AUTOSAR XML (schema 00054)
package /AUTOSAR/Platform/BaseTypes
  7 x base type, all with category=FIXED_LENGTH:
    boolean_bt: base-type-size=8, base-type-encoding=BOOLEAN
    uint8_bt: base-type-size=8, base-type-encoding=NONE
    uint16_bt: base-type-size=16, base-type-encoding=NONE
    uint32_bt: base-type-size=32, base-type-encoding=NONE
    sint8_bt: base-type-size=8, base-type-encoding=2C
    sint16_bt: base-type-size=16, base-type-encoding=2C
    sint32_bt: base-type-size=32, base-type-encoding=2C
package /AUTOSAR/Platform/ImplementationDataTypes
  7 x impl type, all with category=VALUE:
    boolean_T: base-type=boolean_bt
    uint8_T: base-type=uint8_bt
    uint16_T: base-type=uint16_bt
    uint32_T: base-type=uint32_bt
    sint8_T: base-type=sint8_bt
    sint16_T: base-type=sint16_bt
    sint32_T: base-type=sint32_bt
package /Taktflow/System
  system TaktflowSystem: category=SYSTEM_EXTRACT
package /Taktflow/Communication
  can cluster CAN_500k: baudrate=500000, protocol-name=CAN
    can physical channel CAN_Physical: comm-connectors=[CVC_Conn, FZC_Conn, RZC_Conn, SC_Conn, BCM_Conn, ICU_Conn, TCU_Conn, Tester_Conn]
      frame EStop_Broadcast_Frame: id 0x1, frame-length=4, can-addressing-mode=STANDARD, can-frame-rx-behavior=CAN-20, can-frame-tx-behavior=CAN-20
        pdu EStop_Broadcast: length=4
          signal EStop_Broadcast_E2E_DataID: start 0, 4 bit, little-endian, data-type-policy=OVERRIDE, transfer-property=PENDING
          signal EStop_Broadcast_E2E_AliveCounter: start 4, 4 bit, little-endian, data-type-policy=OVERRIDE, transfer-property=PENDING
          signal EStop_Broadcast_E2E_CRC8: start 8, 8 bit, little-endian, data-type-policy=OVERRIDE, transfer-property=PENDING
          signal EStop_Broadcast_EStop_Active: start 16, 8 bit, little-endian, data-type-policy=OVERRIDE, transfer-property=PENDING
          signal EStop_Broadcast_EStop_Source: start 24, 8 bit, little-endian, data-type-policy=OVERRIDE, transfer-property=PENDING
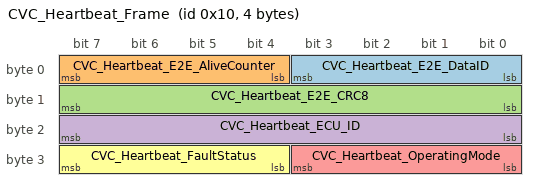
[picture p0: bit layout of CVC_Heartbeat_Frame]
      frame CVC_Heartbeat_Frame: id 0x10, frame-length=4, can-addressing-mode=STANDARD, can-frame-rx-behavior=CAN-20, can-frame-tx-behavior=CAN-20
        pdu CVC_Heartbeat: length=4
          signal CVC_Heartbeat_E2E_DataID: start 0, 4 bit, little-endian, data-type-policy=OVERRIDE, transfer-property=PENDING
          signal CVC_Heartbeat_E2E_AliveCounter: start 4, 4 bit, little-endian, data-type-policy=OVERRIDE, transfer-property=PENDING
          signal CVC_Heartbeat_E2E_CRC8: start 8, 8 bit, little-endian, data-type-policy=OVERRIDE, transfer-property=PENDING
          signal CVC_Heartbeat_ECU_ID: start 16, 8 bit, little-endian, data-type-policy=OVERRIDE, transfer-property=PENDING
          signal CVC_Heartbeat_OperatingMode: start 24, 4 bit, little-endian, data-type-policy=OVERRIDE, transfer-property=PENDING
          signal CVC_Heartbeat_FaultStatus: start 28, 4 bit, little-endian, data-type-policy=OVERRIDE, transfer-property=PENDING
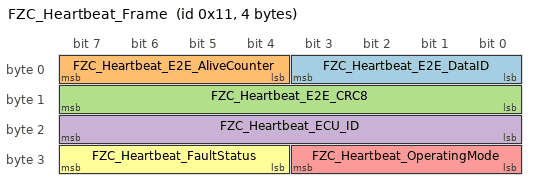
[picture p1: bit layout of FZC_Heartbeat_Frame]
      frame FZC_Heartbeat_Frame: id 0x11, frame-length=4, can-addressing-mode=STANDARD, can-frame-rx-behavior=CAN-20, can-frame-tx-behavior=CAN-20
        pdu FZC_Heartbeat: length=4
          signal FZC_Heartbeat_E2E_DataID: start 0, 4 bit, little-endian, data-type-policy=OVERRIDE, transfer-property=PENDING
          signal FZC_Heartbeat_E2E_AliveCounter: start 4, 4 bit, little-endian, data-type-policy=OVERRIDE, transfer-property=PENDING
          signal FZC_Heartbeat_E2E_CRC8: start 8, 8 bit, little-endian, data-type-policy=OVERRIDE, transfer-property=PENDING
          signal FZC_Heartbeat_ECU_ID: start 16, 8 bit, little-endian, data-type-policy=OVERRIDE, transfer-property=PENDING
          signal FZC_Heartbeat_OperatingMode: start 24, 4 bit, little-endian, data-type-policy=OVERRIDE, transfer-property=PENDING
          signal FZC_Heartbeat_FaultStatus: start 28, 4 bit, little-endian, data-type-policy=OVERRIDE, transfer-property=PENDING
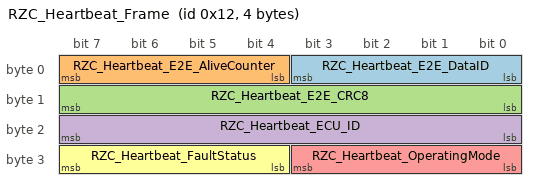
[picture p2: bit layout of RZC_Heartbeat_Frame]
      frame RZC_Heartbeat_Frame: id 0x12, frame-length=4, can-addressing-mode=STANDARD, can-frame-rx-behavior=CAN-20, can-frame-tx-behavior=CAN-20
        pdu RZC_Heartbeat: length=4
          signal RZC_Heartbeat_E2E_DataID: start 0, 4 bit, little-endian, data-type-policy=OVERRIDE, transfer-property=PENDING
          signal RZC_Heartbeat_E2E_AliveCounter: start 4, 4 bit, little-endian, data-type-policy=OVERRIDE, transfer-property=PENDING
          signal RZC_Heartbeat_E2E_CRC8: start 8, 8 bit, little-endian, data-type-policy=OVERRIDE, transfer-property=PENDING
          signal RZC_Heartbeat_ECU_ID: start 16, 8 bit, little-endian, data-type-policy=OVERRIDE, transfer-property=PENDING
          signal RZC_Heartbeat_OperatingMode: start 24, 4 bit, little-endian, data-type-policy=OVERRIDE, transfer-property=PENDING
          signal RZC_Heartbeat_FaultStatus: start 28, 4 bit, little-endian, data-type-policy=OVERRIDE, transfer-property=PENDING
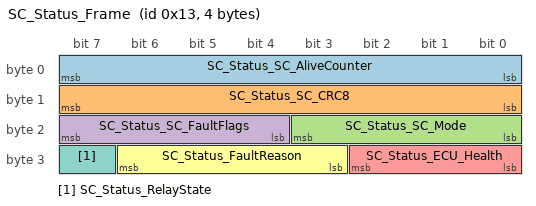
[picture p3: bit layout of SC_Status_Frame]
      frame SC_Status_Frame: id 0x13, frame-length=4, can-addressing-mode=STANDARD, can-frame-rx-behavior=CAN-20, can-frame-tx-behavior=CAN-20
        pdu SC_Status: length=4
          signal SC_Status_SC_AliveCounter: start 0, 8 bit, little-endian, data-type-policy=OVERRIDE, transfer-property=PENDING
          signal SC_Status_SC_CRC8: start 8, 8 bit, little-endian, data-type-policy=OVERRIDE, transfer-property=PENDING
          signal SC_Status_SC_Mode: start 16, 4 bit, little-endian, data-type-policy=OVERRIDE, transfer-property=PENDING
          signal SC_Status_SC_FaultFlags: start 20, 4 bit, little-endian, data-type-policy=OVERRIDE, transfer-property=PENDING
          signal SC_Status_ECU_Health: start 24, 3 bit, little-endian, data-type-policy=OVERRIDE, transfer-property=PENDING
          signal SC_Status_FaultReason: start 27, 4 bit, little-endian, data-type-policy=OVERRIDE, transfer-property=PENDING
          signal SC_Status_RelayState: start 31, 1 bit, little-endian, data-type-policy=OVERRIDE, transfer-property=PENDING
      frame ICU_Heartbeat_Frame: id 0x14, frame-length=4, can-addressing-mode=STANDARD, can-frame-rx-behavior=CAN-20, can-frame-tx-behavior=CAN-20
        pdu ICU_Heartbeat: length=4
          signal ICU_Heartbeat_E2E_DataID: start 0, 4 bit, little-endian, data-type-policy=OVERRIDE, transfer-property=PENDING
          signal ICU_Heartbeat_E2E_AliveCounter: start 4, 4 bit, little-endian, data-type-policy=OVERRIDE, transfer-property=PENDING
          signal ICU_Heartbeat_E2E_CRC8: start 8, 8 bit, little-endian, data-type-policy=OVERRIDE, transfer-property=PENDING
          signal ICU_Heartbeat_AliveCounter: start 16, 8 bit, little-endian, data-type-policy=OVERRIDE, transfer-property=PENDING
          signal ICU_Heartbeat_ECU_ID: start 24, 8 bit, little-endian, data-type-policy=OVERRIDE, transfer-property=PENDING
      frame TCU_Heartbeat_Frame: id 0x15, frame-length=4, can-addressing-mode=STANDARD, can-frame-rx-behavior=CAN-20, can-frame-tx-behavior=CAN-20
        pdu TCU_Heartbeat: length=4
          signal TCU_Heartbeat_E2E_DataID: start 0, 4 bit, little-endian, data-type-policy=OVERRIDE, transfer-property=PENDING
          signal TCU_Heartbeat_E2E_AliveCounter: start 4, 4 bit, little-endian, data-type-policy=OVERRIDE, transfer-property=PENDING
          signal TCU_Heartbeat_E2E_CRC8: start 8, 8 bit, little-endian, data-type-policy=OVERRIDE, transfer-property=PENDING
          signal TCU_Heartbeat_AliveCounter: start 16, 8 bit, little-endian, data-type-policy=OVERRIDE, transfer-property=PENDING
          signal TCU_Heartbeat_ECU_ID: start 24, 8 bit, little-endian, data-type-policy=OVERRIDE, transfer-property=PENDING
      frame BCM_Heartbeat_Frame: id 0x16, frame-length=4, can-addressing-mode=STANDARD, can-frame-rx-behavior=CAN-20, can-frame-tx-behavior=CAN-20
        pdu BCM_Heartbeat: length=4
          signal BCM_Heartbeat_E2E_DataID: start 0, 4 bit, little-endian, data-type-policy=OVERRIDE, transfer-property=PENDING
          signal BCM_Heartbeat_E2E_AliveCounter: start 4, 4 bit, little-endian, data-type-policy=OVERRIDE, transfer-property=PENDING
          signal BCM_Heartbeat_E2E_CRC8: start 8, 8 bit, little-endian, data-type-policy=OVERRIDE, transfer-property=PENDING
          signal BCM_Heartbeat_AliveCounter: start 16, 8 bit, little-endian, data-type-policy=OVERRIDE, transfer-property=PENDING
          signal BCM_Heartbeat_ECU_ID: start 24, 8 bit, little-endian, data-type-policy=OVERRIDE, transfer-property=PENDING
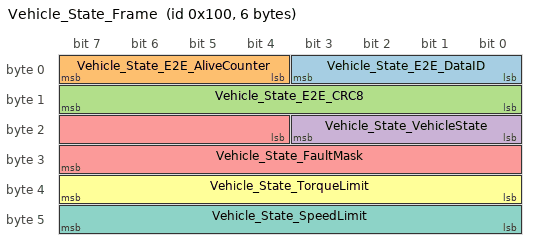
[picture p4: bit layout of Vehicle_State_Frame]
      frame Vehicle_State_Frame: id 0x100, frame-length=6, can-addressing-mode=STANDARD, can-frame-rx-behavior=CAN-20, can-frame-tx-behavior=CAN-20
        pdu Vehicle_State: length=6
          signal Vehicle_State_E2E_DataID: start 0, 4 bit, little-endian, data-type-policy=OVERRIDE, transfer-property=PENDING
          signal Vehicle_State_E2E_AliveCounter: start 4, 4 bit, little-endian, data-type-policy=OVERRIDE, transfer-property=PENDING
          signal Vehicle_State_E2E_CRC8: start 8, 8 bit, little-endian, data-type-policy=OVERRIDE, transfer-property=PENDING
          signal Vehicle_State_VehicleState: start 16, 4 bit, little-endian, data-type-policy=OVERRIDE, transfer-property=PENDING
          signal Vehicle_State_FaultMask: start 20, 12 bit, little-endian, data-type-policy=OVERRIDE, transfer-property=PENDING
          signal Vehicle_State_TorqueLimit: start 32, 8 bit, little-endian, data-type-policy=OVERRIDE, transfer-property=PENDING
          signal Vehicle_State_SpeedLimit: start 40, 8 bit, little-endian, data-type-policy=OVERRIDE, transfer-property=PENDING
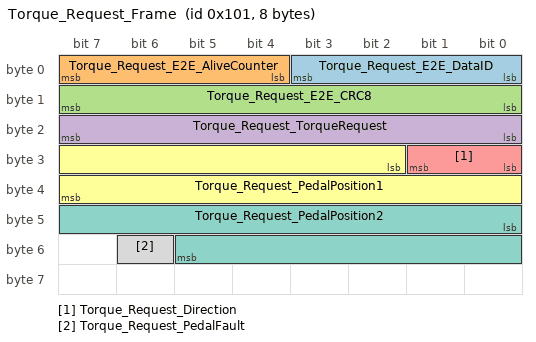
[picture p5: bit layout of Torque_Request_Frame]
      frame Torque_Request_Frame: id 0x101, frame-length=8, can-addressing-mode=STANDARD, can-frame-rx-behavior=CAN-20, can-frame-tx-behavior=CAN-20
        pdu Torque_Request: length=8
          signal Torque_Request_E2E_DataID: start 0, 4 bit, little-endian, data-type-policy=OVERRIDE, transfer-property=PENDING
          signal Torque_Request_E2E_AliveCounter: start 4, 4 bit, little-endian, data-type-policy=OVERRIDE, transfer-property=PENDING
          signal Torque_Request_E2E_CRC8: start 8, 8 bit, little-endian, data-type-policy=OVERRIDE, transfer-property=PENDING
          signal Torque_Request_TorqueRequest: start 16, 8 bit, little-endian, data-type-policy=OVERRIDE, transfer-property=PENDING
          signal Torque_Request_Direction: start 24, 2 bit, little-endian, data-type-policy=OVERRIDE, transfer-property=PENDING
          signal Torque_Request_PedalPosition1: start 26, 14 bit, little-endian, data-type-policy=OVERRIDE, transfer-property=PENDING
          signal Torque_Request_PedalPosition2: start 40, 14 bit, little-endian, data-type-policy=OVERRIDE, transfer-property=PENDING
          signal Torque_Request_PedalFault: start 54, 1 bit, little-endian, data-type-policy=OVERRIDE, transfer-property=PENDING
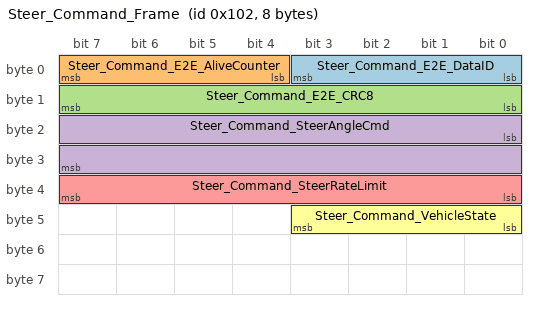
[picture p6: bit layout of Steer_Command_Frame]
      frame Steer_Command_Frame: id 0x102, frame-length=8, can-addressing-mode=STANDARD, can-frame-rx-behavior=CAN-20, can-frame-tx-behavior=CAN-20
        pdu Steer_Command: length=8
          signal Steer_Command_E2E_DataID: start 0, 4 bit, little-endian, data-type-policy=OVERRIDE, transfer-property=PENDING
          signal Steer_Command_E2E_AliveCounter: start 4, 4 bit, little-endian, data-type-policy=OVERRIDE, transfer-property=PENDING
          signal Steer_Command_E2E_CRC8: start 8, 8 bit, little-endian, data-type-policy=OVERRIDE, transfer-property=PENDING
          signal Steer_Command_SteerAngleCmd: start 16, 16 bit, little-endian, data-type-policy=OVERRIDE, transfer-property=PENDING
          signal Steer_Command_SteerRateLimit: start 32, 8 bit, little-endian, data-type-policy=OVERRIDE, transfer-property=PENDING
          signal Steer_Command_VehicleState: start 40, 4 bit, little-endian, data-type-policy=OVERRIDE, transfer-property=PENDING
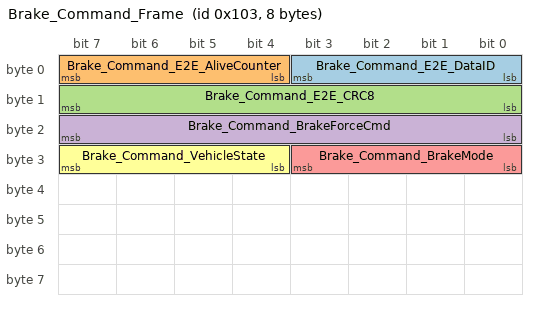
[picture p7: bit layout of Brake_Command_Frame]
      frame Brake_Command_Frame: id 0x103, frame-length=8, can-addressing-mode=STANDARD, can-frame-rx-behavior=CAN-20, can-frame-tx-behavior=CAN-20
        pdu Brake_Command: length=8
          signal Brake_Command_E2E_DataID: start 0, 4 bit, little-endian, data-type-policy=OVERRIDE, transfer-property=PENDING
          signal Brake_Command_E2E_AliveCounter: start 4, 4 bit, little-endian, data-type-policy=OVERRIDE, transfer-property=PENDING
          signal Brake_Command_E2E_CRC8: start 8, 8 bit, little-endian, data-type-policy=OVERRIDE, transfer-property=PENDING
          signal Brake_Command_BrakeForceCmd: start 16, 8 bit, little-endian, data-type-policy=OVERRIDE, transfer-property=PENDING
          signal Brake_Command_BrakeMode: start 24, 4 bit, little-endian, data-type-policy=OVERRIDE, transfer-property=PENDING
          signal Brake_Command_VehicleState: start 28, 4 bit, little-endian, data-type-policy=OVERRIDE, transfer-property=PENDING
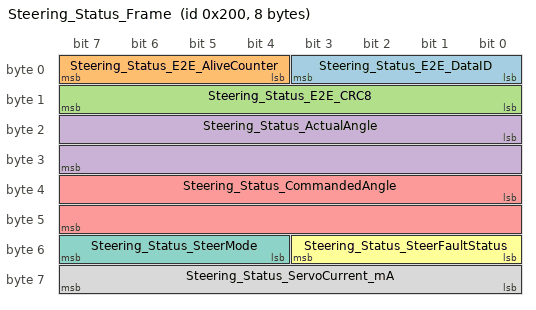
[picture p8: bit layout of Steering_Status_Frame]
      frame Steering_Status_Frame: id 0x200, frame-length=8, can-addressing-mode=STANDARD, can-frame-rx-behavior=CAN-20, can-frame-tx-behavior=CAN-20
        pdu Steering_Status: length=8
          signal Steering_Status_E2E_DataID: start 0, 4 bit, little-endian, data-type-policy=OVERRIDE, transfer-property=PENDING
          signal Steering_Status_E2E_AliveCounter: start 4, 4 bit, little-endian, data-type-policy=OVERRIDE, transfer-property=PENDING
          signal Steering_Status_E2E_CRC8: start 8, 8 bit, little-endian, data-type-policy=OVERRIDE, transfer-property=PENDING
          signal Steering_Status_ActualAngle: start 16, 16 bit, little-endian, data-type-policy=OVERRIDE, transfer-property=PENDING
          signal Steering_Status_CommandedAngle: start 32, 16 bit, little-endian, data-type-policy=OVERRIDE, transfer-property=PENDING
          signal Steering_Status_SteerFaultStatus: start 48, 4 bit, little-endian, data-type-policy=OVERRIDE, transfer-property=PENDING
          signal Steering_Status_SteerMode: start 52, 4 bit, little-endian, data-type-policy=OVERRIDE, transfer-property=PENDING
          signal Steering_Status_ServoCurrent_mA: start 56, 8 bit, little-endian, data-type-policy=OVERRIDE, transfer-property=PENDING
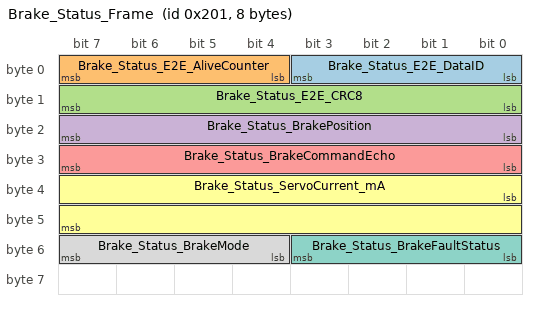
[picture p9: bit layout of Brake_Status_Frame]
      frame Brake_Status_Frame: id 0x201, frame-length=8, can-addressing-mode=STANDARD, can-frame-rx-behavior=CAN-20, can-frame-tx-behavior=CAN-20
        pdu Brake_Status: length=8
          signal Brake_Status_E2E_DataID: start 0, 4 bit, little-endian, data-type-policy=OVERRIDE, transfer-property=PENDING
          signal Brake_Status_E2E_AliveCounter: start 4, 4 bit, little-endian, data-type-policy=OVERRIDE, transfer-property=PENDING
          signal Brake_Status_E2E_CRC8: start 8, 8 bit, little-endian, data-type-policy=OVERRIDE, transfer-property=PENDING
          signal Brake_Status_BrakePosition: start 16, 8 bit, little-endian, data-type-policy=OVERRIDE, transfer-property=PENDING
          signal Brake_Status_BrakeCommandEcho: start 24, 8 bit, little-endian, data-type-policy=OVERRIDE, transfer-property=PENDING
          signal Brake_Status_ServoCurrent_mA: start 32, 16 bit, little-endian, data-type-policy=OVERRIDE, transfer-property=PENDING
          signal Brake_Status_BrakeFaultStatus: start 48, 4 bit, little-endian, data-type-policy=OVERRIDE, transfer-property=PENDING
          signal Brake_Status_BrakeMode: start 52, 4 bit, little-endian, data-type-policy=OVERRIDE, transfer-property=PENDING
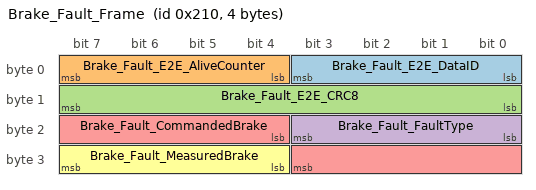
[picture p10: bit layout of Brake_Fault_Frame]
      frame Brake_Fault_Frame: id 0x210, frame-length=4, can-addressing-mode=STANDARD, can-frame-rx-behavior=CAN-20, can-frame-tx-behavior=CAN-20
        pdu Brake_Fault: length=4
          signal Brake_Fault_E2E_DataID: start 0, 4 bit, little-endian, data-type-policy=OVERRIDE, transfer-property=PENDING
          signal Brake_Fault_E2E_AliveCounter: start 4, 4 bit, little-endian, data-type-policy=OVERRIDE, transfer-property=PENDING
          signal Brake_Fault_E2E_CRC8: start 8, 8 bit, little-endian, data-type-policy=OVERRIDE, transfer-property=PENDING
          signal Brake_Fault_FaultType: start 16, 4 bit, little-endian, data-type-policy=OVERRIDE, transfer-property=PENDING
          signal Brake_Fault_CommandedBrake: start 20, 8 bit, little-endian, data-type-policy=OVERRIDE, transfer-property=PENDING
          signal Brake_Fault_MeasuredBrake: start 28, 4 bit, little-endian, data-type-policy=OVERRIDE, transfer-property=PENDING
      frame Motor_Cutoff_Req_Frame: id 0x211, frame-length=4, can-addressing-mode=STANDARD, can-frame-rx-behavior=CAN-20, can-frame-tx-behavior=CAN-20
        pdu Motor_Cutoff_Req: length=4
          signal Motor_Cutoff_Req_E2E_DataID: start 0, 4 bit, little-endian, data-type-policy=OVERRIDE, transfer-property=PENDING
          signal Motor_Cutoff_Req_E2E_AliveCounter: start 4, 4 bit, little-endian, data-type-policy=OVERRIDE, transfer-property=PENDING
          signal Motor_Cutoff_Req_E2E_CRC8: start 8, 8 bit, little-endian, data-type-policy=OVERRIDE, transfer-property=PENDING
          signal Motor_Cutoff_Req_RequestType: start 16, 4 bit, little-endian, data-type-policy=OVERRIDE, transfer-property=PENDING
          signal Motor_Cutoff_Req_Reason: start 20, 4 bit, little-endian, data-type-policy=OVERRIDE, transfer-property=PENDING
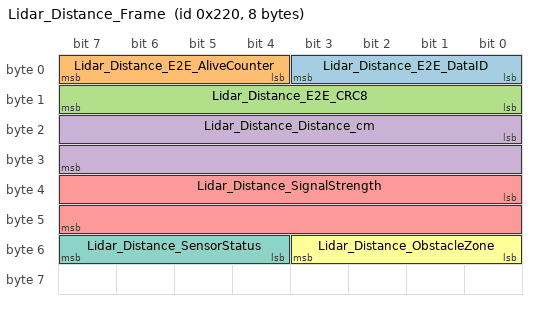
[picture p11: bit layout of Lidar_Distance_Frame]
      frame Lidar_Distance_Frame: id 0x220, frame-length=8, can-addressing-mode=STANDARD, can-frame-rx-behavior=CAN-20, can-frame-tx-behavior=CAN-20
        pdu Lidar_Distance: length=8
          signal Lidar_Distance_E2E_DataID: start 0, 4 bit, little-endian, data-type-policy=OVERRIDE, transfer-property=PENDING
          signal Lidar_Distance_E2E_AliveCounter: start 4, 4 bit, little-endian, data-type-policy=OVERRIDE, transfer-property=PENDING
          signal Lidar_Distance_E2E_CRC8: start 8, 8 bit, little-endian, data-type-policy=OVERRIDE, transfer-property=PENDING
          signal Lidar_Distance_Distance_cm: start 16, 16 bit, little-endian, data-type-policy=OVERRIDE, transfer-property=PENDING
          signal Lidar_Distance_SignalStrength: start 32, 16 bit, little-endian, data-type-policy=OVERRIDE, transfer-property=PENDING
          signal Lidar_Distance_ObstacleZone: start 48, 4 bit, little-endian, data-type-policy=OVERRIDE, transfer-property=PENDING
          signal Lidar_Distance_SensorStatus: start 52, 4 bit, little-endian, data-type-policy=OVERRIDE, transfer-property=PENDING
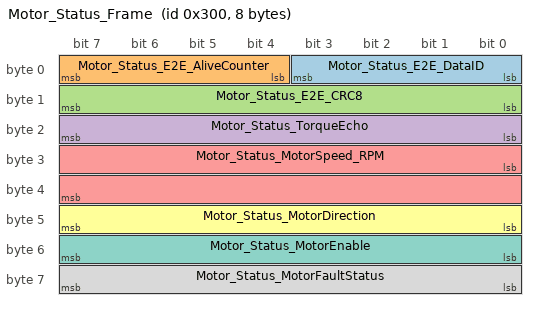
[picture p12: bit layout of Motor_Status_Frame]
      frame Motor_Status_Frame: id 0x300, frame-length=8, can-addressing-mode=STANDARD, can-frame-rx-behavior=CAN-20, can-frame-tx-behavior=CAN-20
        pdu Motor_Status: length=8
          signal Motor_Status_E2E_DataID: start 0, 4 bit, little-endian, data-type-policy=OVERRIDE, transfer-property=PENDING
          signal Motor_Status_E2E_AliveCounter: start 4, 4 bit, little-endian, data-type-policy=OVERRIDE, transfer-property=PENDING
          signal Motor_Status_E2E_CRC8: start 8, 8 bit, little-endian, data-type-policy=OVERRIDE, transfer-property=PENDING
          signal Motor_Status_TorqueEcho: start 16, 8 bit, little-endian, data-type-policy=OVERRIDE, transfer-property=PENDING
          signal Motor_Status_MotorSpeed_RPM: start 24, 16 bit, little-endian, data-type-policy=OVERRIDE, transfer-property=PENDING
          signal Motor_Status_MotorDirection: start 40, 8 bit, little-endian, data-type-policy=OVERRIDE, transfer-property=PENDING
          signal Motor_Status_MotorEnable: start 48, 8 bit, little-endian, data-type-policy=OVERRIDE, transfer-property=PENDING
          signal Motor_Status_MotorFaultStatus: start 56, 8 bit, little-endian, data-type-policy=OVERRIDE, transfer-property=PENDING
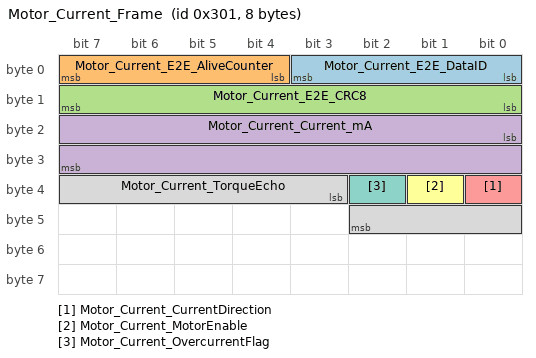
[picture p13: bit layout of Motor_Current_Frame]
      frame Motor_Current_Frame: id 0x301, frame-length=8, can-addressing-mode=STANDARD, can-frame-rx-behavior=CAN-20, can-frame-tx-behavior=CAN-20
        pdu Motor_Current: length=8
          signal Motor_Current_E2E_DataID: start 0, 4 bit, little-endian, data-type-policy=OVERRIDE, transfer-property=PENDING
          signal Motor_Current_E2E_AliveCounter: start 4, 4 bit, little-endian, data-type-policy=OVERRIDE, transfer-property=PENDING
          signal Motor_Current_E2E_CRC8: start 8, 8 bit, little-endian, data-type-policy=OVERRIDE, transfer-property=PENDING
          signal Motor_Current_Current_mA: start 16, 16 bit, little-endian, data-type-policy=OVERRIDE, transfer-property=PENDING
          signal Motor_Current_CurrentDirection: start 32, 1 bit, little-endian, data-type-policy=OVERRIDE, transfer-property=PENDING
          signal Motor_Current_MotorEnable: start 33, 1 bit, little-endian, data-type-policy=OVERRIDE, transfer-property=PENDING
          signal Motor_Current_OvercurrentFlag: start 34, 1 bit, little-endian, data-type-policy=OVERRIDE, transfer-property=PENDING
          signal Motor_Current_TorqueEcho: start 35, 8 bit, little-endian, data-type-policy=OVERRIDE, transfer-property=PENDING
      frame Motor_Temperature_Frame: id 0x302, frame-length=8, can-addressing-mode=STANDARD, can-frame-rx-behavior=CAN-20, can-frame-tx-behavior=CAN-20
        pdu Motor_Temperature: length=8
          signal Motor_Temperature_E2E_DataID: start 0, 4 bit, little-endian, data-type-policy=OVERRIDE, transfer-property=PENDING
          signal Motor_Temperature_E2E_AliveCounter: start 4, 4 bit, little-endian, data-type-policy=OVERRIDE, transfer-property=PENDING
          signal Motor_Temperature_E2E_CRC8: start 8, 8 bit, little-endian, data-type-policy=OVERRIDE, transfer-property=PENDING
          signal Motor_Temperature_WindingTemp1_C: start 16, 16 bit, little-endian, data-type-policy=OVERRIDE, transfer-property=PENDING
          signal Motor_Temperature_WindingTemp2_C: start 32, 16 bit, little-endian, data-type-policy=OVERRIDE, transfer-property=PENDING
          signal Motor_Temperature_DeratingPercent: start 48, 8 bit, little-endian, data-type-policy=OVERRIDE, transfer-property=PENDING
      frame Battery_Status_Frame: id 0x303, frame-length=6, can-addressing-mode=STANDARD, can-frame-rx-behavior=CAN-20, can-frame-tx-behavior=CAN-20
        pdu Battery_Status: length=6
          signal Battery_Status_E2E_DataID: start 0, 4 bit, little-endian, data-type-policy=OVERRIDE, transfer-property=PENDING
          signal Battery_Status_E2E_AliveCounter: start 4, 4 bit, little-endian, data-type-policy=OVERRIDE, transfer-property=PENDING
          signal Battery_Status_E2E_CRC8: start 8, 8 bit, little-endian, data-type-policy=OVERRIDE, transfer-property=PENDING
          signal Battery_Status_BatteryVoltage_mV: start 16, 16 bit, little-endian, data-type-policy=OVERRIDE, transfer-property=PENDING
          signal Battery_Status_BatteryStatus: start 32, 8 bit, little-endian, data-type-policy=OVERRIDE, transfer-property=PENDING
      frame Body_Control_Cmd_Frame: id 0x350, frame-length=4, can-addressing-mode=STANDARD, can-frame-rx-behavior=CAN-20, can-frame-tx-behavior=CAN-20
        pdu Body_Control_Cmd: length=4
          signal Body_Control_Cmd_HeadlightCmd: start 0, 2 bit, little-endian, data-type-policy=OVERRIDE, transfer-property=PENDING
          signal Body_Control_Cmd_TailLightCmd: start 2, 1 bit, little-endian, data-type-policy=OVERRIDE, transfer-property=PENDING
          signal Body_Control_Cmd_HazardCmd: start 3, 1 bit, little-endian, data-type-policy=OVERRIDE, transfer-property=PENDING
          signal Body_Control_Cmd_TurnSignalCmd: start 4, 2 bit, little-endian, data-type-policy=OVERRIDE, transfer-property=PENDING
          signal Body_Control_Cmd_DoorLockCmd: start 6, 1 bit, little-endian, data-type-policy=OVERRIDE, transfer-property=PENDING
      frame Light_Status_Frame: id 0x400, frame-length=4, can-addressing-mode=STANDARD, can-frame-rx-behavior=CAN-20, can-frame-tx-behavior=CAN-20
        pdu Light_Status: length=4
          signal Light_Status_HeadlightOn: start 0, 1 bit, little-endian, data-type-policy=OVERRIDE, transfer-property=PENDING
          signal Light_Status_TailLightOn: start 1, 1 bit, little-endian, data-type-policy=OVERRIDE, transfer-property=PENDING
          signal Light_Status_FogLightOn: start 2, 1 bit, little-endian, data-type-policy=OVERRIDE, transfer-property=PENDING
          signal Light_Status_BrakeLightOn: start 3, 1 bit, little-endian, data-type-policy=OVERRIDE, transfer-property=PENDING
          signal Light_Status_HeadlightLevel: start 4, 2 bit, little-endian, data-type-policy=OVERRIDE, transfer-property=PENDING
      frame Indicator_State_Frame: id 0x401, frame-length=4, can-addressing-mode=STANDARD, can-frame-rx-behavior=CAN-20, can-frame-tx-behavior=CAN-20
        pdu Indicator_State: length=4
          signal Indicator_State_LeftIndicator: start 0, 1 bit, little-endian, data-type-policy=OVERRIDE, transfer-property=PENDING
          signal Indicator_State_RightIndicator: start 1, 1 bit, little-endian, data-type-policy=OVERRIDE, transfer-property=PENDING
          signal Indicator_State_HazardActive: start 2, 1 bit, little-endian, data-type-policy=OVERRIDE, transfer-property=PENDING
          signal Indicator_State_BlinkState: start 3, 1 bit, little-endian, data-type-policy=OVERRIDE, transfer-property=PENDING
      frame Door_Lock_Status_Frame: id 0x402, frame-length=2, can-addressing-mode=STANDARD, can-frame-rx-behavior=CAN-20, can-frame-tx-behavior=CAN-20
        pdu Door_Lock_Status: length=2
          signal Door_Lock_Status_FrontLeftLock: start 0, 1 bit, little-endian, data-type-policy=OVERRIDE, transfer-property=PENDING
          signal Door_Lock_Status_FrontRightLock: start 1, 1 bit, little-endian, data-type-policy=OVERRIDE, transfer-property=PENDING
          signal Door_Lock_Status_RearLeftLock: start 2, 1 bit, little-endian, data-type-policy=OVERRIDE, transfer-property=PENDING
          signal Door_Lock_Status_RearRightLock: start 3, 1 bit, little-endian, data-type-policy=OVERRIDE, transfer-property=PENDING
          signal Door_Lock_Status_CentralLock: start 4, 1 bit, little-endian, data-type-policy=OVERRIDE, transfer-property=PENDING
      frame DTC_Broadcast_Frame: id 0x500, frame-length=8, can-addressing-mode=STANDARD, can-frame-rx-behavior=CAN-20, can-frame-tx-behavior=CAN-20
        pdu DTC_Broadcast: length=8
          signal DTC_Broadcast_DTC_Number: start 7, 24 bit, big-endian, data-type-policy=OVERRIDE, transfer-property=PENDING
          signal DTC_Broadcast_DTC_Status: start 24, 8 bit, little-endian, data-type-policy=OVERRIDE, transfer-property=PENDING
          signal DTC_Broadcast_ECU_Source: start 32, 8 bit, little-endian, data-type-policy=OVERRIDE, transfer-property=PENDING
          signal DTC_Broadcast_OccurrenceCount: start 40, 8 bit, little-endian, data-type-policy=OVERRIDE, transfer-property=PENDING
          signal DTC_Broadcast_FreezeFrame0: start 48, 8 bit, little-endian, data-type-policy=OVERRIDE, transfer-property=PENDING
          signal DTC_Broadcast_FreezeFrame1: start 56, 8 bit, little-endian, data-type-policy=OVERRIDE, transfer-property=PENDING
      frame UDS_Func_Request_Frame: id 0x7DF, frame-length=8, can-addressing-mode=STANDARD, can-frame-rx-behavior=CAN-20, can-frame-tx-behavior=CAN-20
        pdu UDS_Func_Request: length=8
          signal UDS_Func_Request_UDS_Data: start 0, 64 bit, little-endian, data-type-policy=OVERRIDE, transfer-property=PENDING
      frame UDS_Phys_Req_CVC_Frame: id 0x7E0, frame-length=8, can-addressing-mode=STANDARD, can-frame-rx-behavior=CAN-20, can-frame-tx-behavior=CAN-20
        pdu UDS_Phys_Req_CVC: length=8
          signal UDS_Phys_Req_CVC_UDS_Data: start 0, 64 bit, little-endian, data-type-policy=OVERRIDE, transfer-property=PENDING
      frame UDS_Phys_Req_FZC_Frame: id 0x7E1, frame-length=8, can-addressing-mode=STANDARD, can-frame-rx-behavior=CAN-20, can-frame-tx-behavior=CAN-20
        pdu UDS_Phys_Req_FZC: length=8
          signal UDS_Phys_Req_FZC_UDS_Data: start 0, 64 bit, little-endian, data-type-policy=OVERRIDE, transfer-property=PENDING
      frame UDS_Phys_Req_RZC_Frame: id 0x7E2, frame-length=8, can-addressing-mode=STANDARD, can-frame-rx-behavior=CAN-20, can-frame-tx-behavior=CAN-20
        pdu UDS_Phys_Req_RZC: length=8
          signal UDS_Phys_Req_RZC_UDS_Data: start 0, 64 bit, little-endian, data-type-policy=OVERRIDE, transfer-property=PENDING
      frame UDS_Phys_Req_TCU_Frame: id 0x7E3, frame-length=8, can-addressing-mode=STANDARD, can-frame-rx-behavior=CAN-20, can-frame-tx-behavior=CAN-20
        pdu UDS_Phys_Req_TCU: length=8
          signal UDS_Phys_Req_TCU_UDS_Data: start 0, 64 bit, little-endian, data-type-policy=OVERRIDE, transfer-property=PENDING
      frame UDS_Resp_CVC_Frame: id 0x7E8, frame-length=8, can-addressing-mode=STANDARD, can-frame-rx-behavior=CAN-20, can-frame-tx-behavior=CAN-20
        pdu UDS_Resp_CVC: length=8
          signal UDS_Resp_CVC_UDS_Data: start 0, 64 bit, little-endian, data-type-policy=OVERRIDE, transfer-property=PENDING
      frame UDS_Resp_FZC_Frame: id 0x7E9, frame-length=8, can-addressing-mode=STANDARD, can-frame-rx-behavior=CAN-20, can-frame-tx-behavior=CAN-20
        pdu UDS_Resp_FZC: length=8
          signal UDS_Resp_FZC_UDS_Data: start 0, 64 bit, little-endian, data-type-policy=OVERRIDE, transfer-property=PENDING
      frame UDS_Resp_RZC_Frame: id 0x7EA, frame-length=8, can-addressing-mode=STANDARD, can-frame-rx-behavior=CAN-20, can-frame-tx-behavior=CAN-20
        pdu UDS_Resp_RZC: length=8
          signal UDS_Resp_RZC_UDS_Data: start 0, 64 bit, little-endian, data-type-policy=OVERRIDE, transfer-property=PENDING
      frame UDS_Resp_TCU_Frame: id 0x644, frame-length=8, can-addressing-mode=STANDARD, can-frame-rx-behavior=CAN-20, can-frame-tx-behavior=CAN-20
        pdu UDS_Resp_TCU: length=8
          signal UDS_Resp_TCU_UDS_Data: start 0, 64 bit, little-endian, data-type-policy=OVERRIDE, transfer-property=PENDING
package /Taktflow/ECUs
  8 x ecu instance:
    CVC
      can communication controller CVC_CanCtrl
      can communication connector CVC_Conn: comm-controller=CVC_CanCtrl
    FZC
      can communication controller FZC_CanCtrl
      can communication connector FZC_Conn: comm-controller=FZC_CanCtrl
    RZC
      can communication controller RZC_CanCtrl
      can communication connector RZC_Conn: comm-controller=RZC_CanCtrl
    SC
      can communication controller SC_CanCtrl
      can communication connector SC_Conn: comm-controller=SC_CanCtrl
    BCM
      can communication controller BCM_CanCtrl
      can communication connector BCM_Conn: comm-controller=BCM_CanCtrl
    ICU
      can communication controller ICU_CanCtrl
      can communication connector ICU_Conn: comm-controller=ICU_CanCtrl
    TCU
      can communication controller TCU_CanCtrl
      can communication connector TCU_Conn: comm-controller=TCU_CanCtrl
    Tester
      can communication controller Tester_CanCtrl
      can communication connector Tester_Conn: comm-controller=Tester_CanCtrl
package /Taktflow/DataTypes
  compu method CM_EStop_Source: 0=CVC_button, 1=CAN_request, 2=SC_relay
  compu method CM_OperatingMode: 0=INIT, 1=RUN, 2=DEGRADED, 3=LIMP, 4=SAFE_STOP, 5=SHUTDOWN
  compu method CM_SC_Mode: 0=INIT, 1=MONITORING, 2=FAULT_DETECTED, 3=SAFE_STOP
  compu method CM_VehicleState: 0=INIT, 1=RUN, 2=DEGRADED, 3=LIMP, 4=SAFE_STOP, 5=SHUTDOWN
  compu method CM_Direction: 0=stopped, 1=forward, 2=reverse
  compu method CM_PedalPosition1: phys=raw*0.022 for raw 0..359.98
  compu method CM_PedalPosition2: phys=raw*0.022 for raw 0..359.98
  compu method CM_SteerAngleCmd: phys=raw*0.01-45 for raw -45..45
  compu method CM_SteerRateLimit: phys=raw*0.2 for raw 0..51
  compu method CM_BrakeMode: 0=release, 1=normal, 2=emergency, 3=auto
  compu method CM_SteerMode: 0=normal, 1=return_center, 2=disabled, 3=local
  compu method CM_ServoCurrent_mA: phys=raw*10 for raw 0..2550
  compu method CM_FaultType: 0=PWM_mismatch, 1=servo_stuck, 2=overcurrent, 3=timeout
  compu method CM_MeasuredBrake: phys=raw*10 for raw 0..100
  compu method CM_RequestType: 0=motor_cutoff, 1=speed_reduce, 2=e_stop_fwd
  compu method CM_Reason: 0=brake_fault, 1=steer_fault, 2=lidar_emergency, 3=CAN_loss
  compu method CM_ObstacleZone: 0=emergency, 1=braking, 2=warning, 3=clear
  compu method CM_MotorDirection: 0=stopped, 1=forward, 2=reverse
  compu method CM_CurrentDirection: 0=forward, 1=reverse
  compu method CM_WindingTemp1_C: phys=raw*0.1 for raw 0..200
  compu method CM_WindingTemp2_C: phys=raw*0.1 for raw 0..200
  compu method CM_BatteryStatus: 0=critical_UV, 1=UV_warn, 2=normal, 3=OV_warn, 4=critical_OV
  compu method CM_HeadlightCmd: 0=off, 1=low, 2=high
  compu method CM_TurnSignalCmd: 0=off, 1=left, 2=right
  compu method CM_HeadlightLevel: 0=off, 1=low, 2=high
  compu method CM_ECU_Source: 1=CVC, 2=FZC, 3=RZC, 4=SC, 5=BCM, 6=ICU, 7=TCU
package /Taktflow/Interfaces
  85 x sender receiver interface:
    SRI_E2E_DataID
      data E2E_DataID: type=uint8_T
    SRI_E2E_AliveCounter
      data E2E_AliveCounter: type=uint8_T
    SRI_E2E_CRC8
      data E2E_CRC8: type=uint8_T
    SRI_EStop_Active
      data EStop_Active: type=uint8_T
    SRI_EStop_Source
      data EStop_Source: type=uint8_T
    SRI_ECU_ID
      data ECU_ID: type=uint8_T
    SRI_OperatingMode
      data OperatingMode: type=uint8_T
    SRI_FaultStatus
      data FaultStatus: type=uint8_T
    SRI_SC_AliveCounter
      data SC_AliveCounter: type=uint8_T
    SRI_SC_CRC8
      data SC_CRC8: type=uint8_T
    SRI_SC_Mode
      data SC_Mode: type=uint8_T
    SRI_SC_FaultFlags
      data SC_FaultFlags: type=uint8_T
    SRI_ECU_Health
      data ECU_Health: type=uint8_T
    SRI_FaultReason
      data FaultReason: type=uint8_T
    SRI_RelayState
      data RelayState: type=boolean_T
    SRI_AliveCounter
      data AliveCounter: type=uint8_T
    SRI_VehicleState
      data VehicleState: type=uint8_T
    SRI_FaultMask
      data FaultMask: type=uint16_T
    SRI_TorqueLimit
      data TorqueLimit: type=uint8_T
    SRI_SpeedLimit
      data SpeedLimit: type=uint8_T
    SRI_TorqueRequest
      data TorqueRequest: type=uint8_T
    SRI_Direction
      data Direction: type=uint8_T
    SRI_PedalPosition1
      data PedalPosition1: type=uint16_T
    SRI_PedalPosition2
      data PedalPosition2: type=uint16_T
    SRI_PedalFault
      data PedalFault: type=boolean_T
    SRI_SteerAngleCmd
      data SteerAngleCmd: type=uint16_T
    SRI_SteerRateLimit
      data SteerRateLimit: type=uint8_T
    SRI_BrakeForceCmd
      data BrakeForceCmd: type=uint8_T
    SRI_BrakeMode
      data BrakeMode: type=uint8_T
    SRI_ActualAngle
      data ActualAngle: type=sint16_T
    SRI_CommandedAngle
      data CommandedAngle: type=sint16_T
    SRI_SteerFaultStatus
      data SteerFaultStatus: type=uint8_T
    SRI_SteerMode
      data SteerMode: type=uint8_T
    SRI_ServoCurrent_mA
      data ServoCurrent_mA: type=uint8_T
    SRI_BrakePosition
      data BrakePosition: type=uint8_T
    SRI_BrakeCommandEcho
      data BrakeCommandEcho: type=uint8_T
    SRI_BrakeFaultStatus
      data BrakeFaultStatus: type=uint8_T
    SRI_FaultType
      data FaultType: type=uint8_T
    SRI_CommandedBrake
      data CommandedBrake: type=uint8_T
    SRI_MeasuredBrake
      data MeasuredBrake: type=uint8_T
    SRI_RequestType
      data RequestType: type=uint8_T
    SRI_Reason
      data Reason: type=uint8_T
    SRI_Distance_cm
      data Distance_cm: type=uint16_T
    SRI_SignalStrength
      data SignalStrength: type=uint16_T
    SRI_ObstacleZone
      data ObstacleZone: type=uint8_T
    SRI_SensorStatus
      data SensorStatus: type=uint8_T
    SRI_TorqueEcho
      data TorqueEcho: type=uint8_T
    SRI_MotorSpeed_RPM
      data MotorSpeed_RPM: type=uint16_T
    SRI_MotorDirection
      data MotorDirection: type=uint8_T
    SRI_MotorEnable
      data MotorEnable: type=uint8_T
    SRI_MotorFaultStatus
      data MotorFaultStatus: type=uint8_T
    SRI_Current_mA
      data Current_mA: type=uint16_T
    SRI_CurrentDirection
      data CurrentDirection: type=boolean_T
    SRI_OvercurrentFlag
      data OvercurrentFlag: type=boolean_T
    SRI_WindingTemp1_C
      data WindingTemp1_C: type=uint16_T
    SRI_WindingTemp2_C
      data WindingTemp2_C: type=uint16_T
    SRI_DeratingPercent
      data DeratingPercent: type=uint8_T
    SRI_BatteryVoltage_mV
      data BatteryVoltage_mV: type=uint16_T
    SRI_BatteryStatus
      data BatteryStatus: type=uint8_T
    SRI_HeadlightCmd
      data HeadlightCmd: type=uint8_T
    SRI_TailLightCmd
      data TailLightCmd: type=boolean_T
    SRI_HazardCmd
      data HazardCmd: type=boolean_T
    SRI_TurnSignalCmd
      data TurnSignalCmd: type=uint8_T
    SRI_DoorLockCmd
      data DoorLockCmd: type=boolean_T
    SRI_HeadlightOn
      data HeadlightOn: type=boolean_T
    SRI_TailLightOn
      data TailLightOn: type=boolean_T
    SRI_FogLightOn
      data FogLightOn: type=boolean_T
    SRI_BrakeLightOn
      data BrakeLightOn: type=boolean_T
    SRI_HeadlightLevel
      data HeadlightLevel: type=uint8_T
    SRI_LeftIndicator
      data LeftIndicator: type=boolean_T
    SRI_RightIndicator
      data RightIndicator: type=boolean_T
    SRI_HazardActive
      data HazardActive: type=boolean_T
    SRI_BlinkState
      data BlinkState: type=boolean_T
    SRI_FrontLeftLock
      data FrontLeftLock: type=boolean_T
    SRI_FrontRightLock
      data FrontRightLock: type=boolean_T
    SRI_RearLeftLock
      data RearLeftLock: type=boolean_T
    SRI_RearRightLock
      data RearRightLock: type=boolean_T
    SRI_CentralLock
      data CentralLock: type=boolean_T
    SRI_DTC_Number
      data DTC_Number: type=uint32_T
    SRI_DTC_Status
      data DTC_Status: type=uint8_T
    SRI_ECU_Source
      data ECU_Source: type=uint8_T
    SRI_OccurrenceCount
      data OccurrenceCount: type=uint8_T
    SRI_FreezeFrame0
      data FreezeFrame0: type=uint8_T
    SRI_FreezeFrame1
      data FreezeFrame1: type=uint8_T
    SRI_UDS_Data
      data UDS_Data: type=uint32_T
package /Taktflow/E2E
  20 x system signal:
    E2E_EStop_Broadcast  # E2E Profile: DataID(4bit)+AliveCounter(4bit)+CRC8. CAN ID: 0x001. ASIL: B. Cycle: 10ms.
    E2E_CVC_Heartbeat  # E2E Profile: DataID(4bit)+AliveCounter(4bit)+CRC8. CAN ID: 0x010. ASIL: C. Cycle: 50ms.
    E2E_FZC_Heartbeat  # E2E Profile: DataID(4bit)+AliveCounter(4bit)+CRC8. CAN ID: 0x011. ASIL: C. Cycle: 50ms.
    E2E_RZC_Heartbeat  # E2E Profile: DataID(4bit)+AliveCounter(4bit)+CRC8. CAN ID: 0x012. ASIL: C. Cycle: 50ms.
    E2E_ICU_Heartbeat  # E2E Profile: DataID(4bit)+AliveCounter(4bit)+CRC8. CAN ID: 0x014. ASIL: QM. Cycle: 500ms.
    E2E_TCU_Heartbeat  # E2E Profile: DataID(4bit)+AliveCounter(4bit)+CRC8. CAN ID: 0x015. ASIL: QM. Cycle: 500ms.
    E2E_BCM_Heartbeat  # E2E Profile: DataID(4bit)+AliveCounter(4bit)+CRC8. CAN ID: 0x016. ASIL: QM. Cycle: ?ms.
    E2E_Vehicle_State  # E2E Profile: DataID(4bit)+AliveCounter(4bit)+CRC8. CAN ID: 0x100. ASIL: D. Cycle: 10ms.
    E2E_Torque_Request  # E2E Profile: DataID(4bit)+AliveCounter(4bit)+CRC8. CAN ID: 0x101. ASIL: D. Cycle: 10ms.
    E2E_Steer_Command  # E2E Profile: DataID(4bit)+AliveCounter(4bit)+CRC8. CAN ID: 0x102. ASIL: D. Cycle: 10ms.
    E2E_Brake_Command  # E2E Profile: DataID(4bit)+AliveCounter(4bit)+CRC8. CAN ID: 0x103. ASIL: D. Cycle: 10ms.
    E2E_Steering_Status  # E2E Profile: DataID(4bit)+AliveCounter(4bit)+CRC8. CAN ID: 0x200. ASIL: D. Cycle: 20ms.
    E2E_Brake_Status  # E2E Profile: DataID(4bit)+AliveCounter(4bit)+CRC8. CAN ID: 0x201. ASIL: D. Cycle: 20ms.
    E2E_Brake_Fault  # E2E Profile: DataID(4bit)+AliveCounter(4bit)+CRC8. CAN ID: 0x210. ASIL: D. Cycle: 0ms.
    E2E_Motor_Cutoff_Req  # E2E Profile: DataID(4bit)+AliveCounter(4bit)+CRC8. CAN ID: 0x211. ASIL: D. Cycle: 10ms.
    E2E_Lidar_Distance  # E2E Profile: DataID(4bit)+AliveCounter(4bit)+CRC8. CAN ID: 0x220. ASIL: C. Cycle: 10ms.
    E2E_Motor_Status  # E2E Profile: DataID(4bit)+AliveCounter(4bit)+CRC8. CAN ID: 0x300. ASIL: D. Cycle: 20ms.
    E2E_Motor_Current  # E2E Profile: DataID(4bit)+AliveCounter(4bit)+CRC8. CAN ID: 0x301. ASIL: C. Cycle: 10ms.
    E2E_Motor_Temperature  # E2E Profile: DataID(4bit)+AliveCounter(4bit)+CRC8. CAN ID: 0x302. ASIL: A. Cycle: 100ms.
    E2E_Battery_Status  # E2E Profile: DataID(4bit)+AliveCounter(4bit)+CRC8. CAN ID: 0x303. ASIL: QM. Cycle: 1000ms.
package /Taktflow/SWCs/CVC
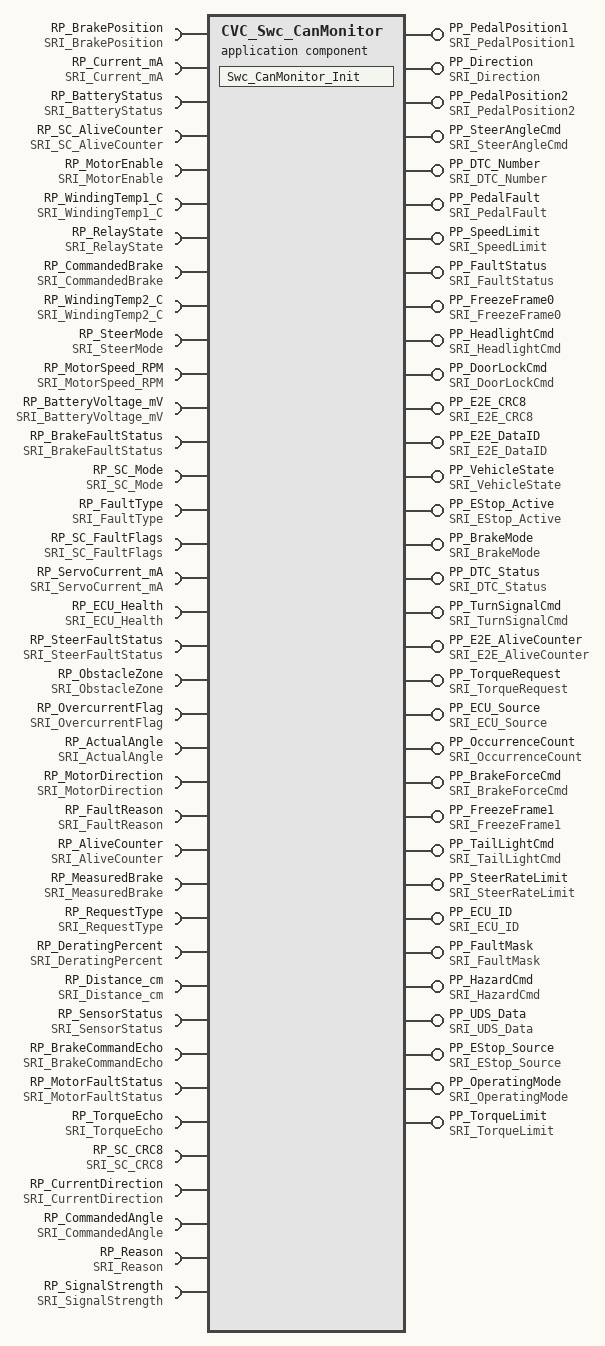
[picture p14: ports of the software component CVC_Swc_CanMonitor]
  application sw component type CVC_Swc_CanMonitor
    33 x provide port:
      PP_PedalPosition1: provided-interface=SRI_PedalPosition1
      PP_Direction: provided-interface=SRI_Direction
      PP_PedalPosition2: provided-interface=SRI_PedalPosition2
      PP_SteerAngleCmd: provided-interface=SRI_SteerAngleCmd
      PP_DTC_Number: provided-interface=SRI_DTC_Number
      PP_PedalFault: provided-interface=SRI_PedalFault
      PP_SpeedLimit: provided-interface=SRI_SpeedLimit
      PP_FaultStatus: provided-interface=SRI_FaultStatus
      PP_FreezeFrame0: provided-interface=SRI_FreezeFrame0
      PP_HeadlightCmd: provided-interface=SRI_HeadlightCmd
      PP_DoorLockCmd: provided-interface=SRI_DoorLockCmd
      PP_E2E_CRC8: provided-interface=SRI_E2E_CRC8
      PP_E2E_DataID: provided-interface=SRI_E2E_DataID
      PP_VehicleState: provided-interface=SRI_VehicleState
      PP_EStop_Active: provided-interface=SRI_EStop_Active
      PP_BrakeMode: provided-interface=SRI_BrakeMode
      PP_DTC_Status: provided-interface=SRI_DTC_Status
      PP_TurnSignalCmd: provided-interface=SRI_TurnSignalCmd
      PP_E2E_AliveCounter: provided-interface=SRI_E2E_AliveCounter
      PP_TorqueRequest: provided-interface=SRI_TorqueRequest
      PP_ECU_Source: provided-interface=SRI_ECU_Source
      PP_OccurrenceCount: provided-interface=SRI_OccurrenceCount
      PP_BrakeForceCmd: provided-interface=SRI_BrakeForceCmd
      PP_FreezeFrame1: provided-interface=SRI_FreezeFrame1
      PP_TailLightCmd: provided-interface=SRI_TailLightCmd
      PP_SteerRateLimit: provided-interface=SRI_SteerRateLimit
      PP_ECU_ID: provided-interface=SRI_ECU_ID
      PP_FaultMask: provided-interface=SRI_FaultMask
      PP_HazardCmd: provided-interface=SRI_HazardCmd
      PP_UDS_Data: provided-interface=SRI_UDS_Data
      PP_EStop_Source: provided-interface=SRI_EStop_Source
      PP_OperatingMode: provided-interface=SRI_OperatingMode
      PP_TorqueLimit: provided-interface=SRI_TorqueLimit
    38 x require port:
      RP_BrakePosition: required-interface=SRI_BrakePosition
      RP_Current_mA: required-interface=SRI_Current_mA
      RP_BatteryStatus: required-interface=SRI_BatteryStatus
      RP_SC_AliveCounter: required-interface=SRI_SC_AliveCounter
      RP_MotorEnable: required-interface=SRI_MotorEnable
      RP_WindingTemp1_C: required-interface=SRI_WindingTemp1_C
      RP_RelayState: required-interface=SRI_RelayState
      RP_CommandedBrake: required-interface=SRI_CommandedBrake
      RP_WindingTemp2_C: required-interface=SRI_WindingTemp2_C
      RP_SteerMode: required-interface=SRI_SteerMode
      RP_MotorSpeed_RPM: required-interface=SRI_MotorSpeed_RPM
      RP_BatteryVoltage_mV: required-interface=SRI_BatteryVoltage_mV
      RP_BrakeFaultStatus: required-interface=SRI_BrakeFaultStatus
      RP_SC_Mode: required-interface=SRI_SC_Mode
      RP_FaultType: required-interface=SRI_FaultType
      RP_SC_FaultFlags: required-interface=SRI_SC_FaultFlags
      RP_ServoCurrent_mA: required-interface=SRI_ServoCurrent_mA
      RP_ECU_Health: required-interface=SRI_ECU_Health
      RP_SteerFaultStatus: required-interface=SRI_SteerFaultStatus
      RP_ObstacleZone: required-interface=SRI_ObstacleZone
      RP_OvercurrentFlag: required-interface=SRI_OvercurrentFlag
      RP_ActualAngle: required-interface=SRI_ActualAngle
      RP_MotorDirection: required-interface=SRI_MotorDirection
      RP_FaultReason: required-interface=SRI_FaultReason
      RP_AliveCounter: required-interface=SRI_AliveCounter
      RP_MeasuredBrake: required-interface=SRI_MeasuredBrake
      RP_RequestType: required-interface=SRI_RequestType
      RP_DeratingPercent: required-interface=SRI_DeratingPercent
      RP_Distance_cm: required-interface=SRI_Distance_cm
      RP_SensorStatus: required-interface=SRI_SensorStatus
      RP_BrakeCommandEcho: required-interface=SRI_BrakeCommandEcho
      RP_MotorFaultStatus: required-interface=SRI_MotorFaultStatus
      RP_TorqueEcho: required-interface=SRI_TorqueEcho
      RP_SC_CRC8: required-interface=SRI_SC_CRC8
      RP_CurrentDirection: required-interface=SRI_CurrentDirection
      RP_CommandedAngle: required-interface=SRI_CommandedAngle
      RP_Reason: required-interface=SRI_Reason
      RP_SignalStrength: required-interface=SRI_SignalStrength
    behavior CVC_Swc_CanMonitor_IB
      init event IE_Swc_CanMonitor_Init: start-on-event=Swc_CanMonitor_Init
      runnable Swc_CanMonitor_Init
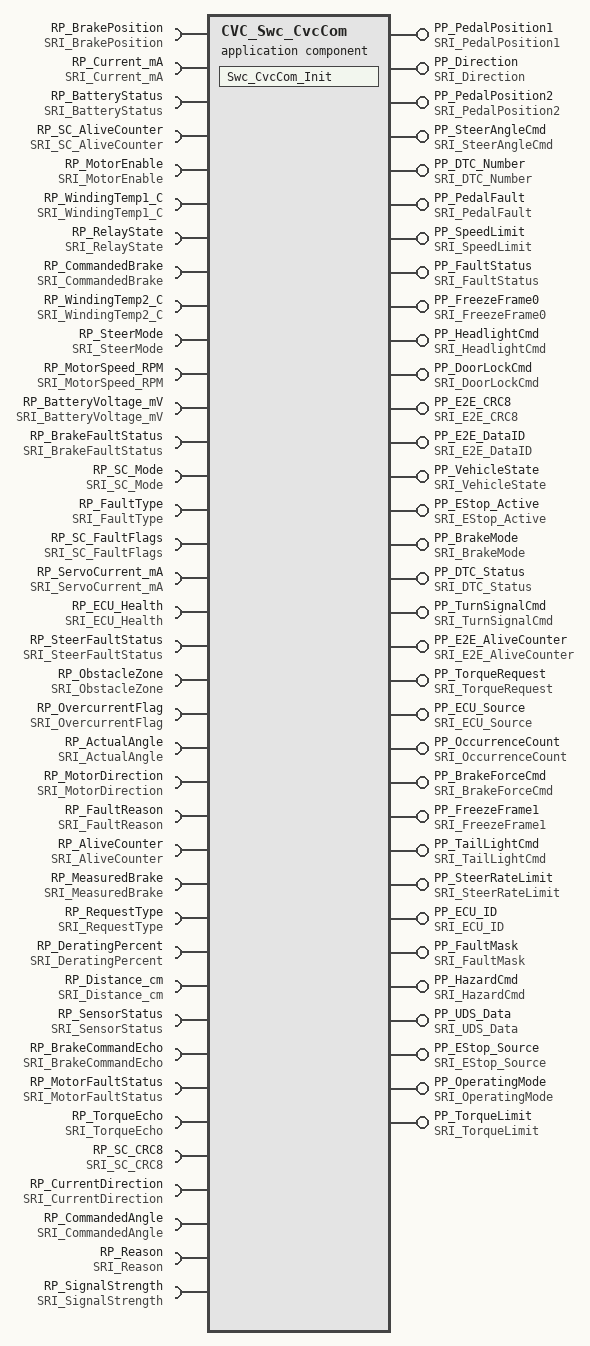
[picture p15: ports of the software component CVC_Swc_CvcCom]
  application sw component type CVC_Swc_CvcCom
    33 x provide port:
      PP_PedalPosition1: provided-interface=SRI_PedalPosition1
      PP_Direction: provided-interface=SRI_Direction
      PP_PedalPosition2: provided-interface=SRI_PedalPosition2
      PP_SteerAngleCmd: provided-interface=SRI_SteerAngleCmd
      PP_DTC_Number: provided-interface=SRI_DTC_Number
      PP_PedalFault: provided-interface=SRI_PedalFault
      PP_SpeedLimit: provided-interface=SRI_SpeedLimit
      PP_FaultStatus: provided-interface=SRI_FaultStatus
      PP_FreezeFrame0: provided-interface=SRI_FreezeFrame0
      PP_HeadlightCmd: provided-interface=SRI_HeadlightCmd
      PP_DoorLockCmd: provided-interface=SRI_DoorLockCmd
      PP_E2E_CRC8: provided-interface=SRI_E2E_CRC8
      PP_E2E_DataID: provided-interface=SRI_E2E_DataID
      PP_VehicleState: provided-interface=SRI_VehicleState
      PP_EStop_Active: provided-interface=SRI_EStop_Active
      PP_BrakeMode: provided-interface=SRI_BrakeMode
      PP_DTC_Status: provided-interface=SRI_DTC_Status
      PP_TurnSignalCmd: provided-interface=SRI_TurnSignalCmd
      PP_E2E_AliveCounter: provided-interface=SRI_E2E_AliveCounter
      PP_TorqueRequest: provided-interface=SRI_TorqueRequest
      PP_ECU_Source: provided-interface=SRI_ECU_Source
      PP_OccurrenceCount: provided-interface=SRI_OccurrenceCount
      PP_BrakeForceCmd: provided-interface=SRI_BrakeForceCmd
      PP_FreezeFrame1: provided-interface=SRI_FreezeFrame1
      PP_TailLightCmd: provided-interface=SRI_TailLightCmd
      PP_SteerRateLimit: provided-interface=SRI_SteerRateLimit
      PP_ECU_ID: provided-interface=SRI_ECU_ID
      PP_FaultMask: provided-interface=SRI_FaultMask
      PP_HazardCmd: provided-interface=SRI_HazardCmd
      PP_UDS_Data: provided-interface=SRI_UDS_Data
      PP_EStop_Source: provided-interface=SRI_EStop_Source
      PP_OperatingMode: provided-interface=SRI_OperatingMode
      PP_TorqueLimit: provided-interface=SRI_TorqueLimit
    38 x require port:
      RP_BrakePosition: required-interface=SRI_BrakePosition
      RP_Current_mA: required-interface=SRI_Current_mA
      RP_BatteryStatus: required-interface=SRI_BatteryStatus
      RP_SC_AliveCounter: required-interface=SRI_SC_AliveCounter
      RP_MotorEnable: required-interface=SRI_MotorEnable
      RP_WindingTemp1_C: required-interface=SRI_WindingTemp1_C
      RP_RelayState: required-interface=SRI_RelayState
      RP_CommandedBrake: required-interface=SRI_CommandedBrake
      RP_WindingTemp2_C: required-interface=SRI_WindingTemp2_C
      RP_SteerMode: required-interface=SRI_SteerMode
      RP_MotorSpeed_RPM: required-interface=SRI_MotorSpeed_RPM
      RP_BatteryVoltage_mV: required-interface=SRI_BatteryVoltage_mV
      RP_BrakeFaultStatus: required-interface=SRI_BrakeFaultStatus
      RP_SC_Mode: required-interface=SRI_SC_Mode
      RP_FaultType: required-interface=SRI_FaultType
      RP_SC_FaultFlags: required-interface=SRI_SC_FaultFlags
      RP_ServoCurrent_mA: required-interface=SRI_ServoCurrent_mA
      RP_ECU_Health: required-interface=SRI_ECU_Health
      RP_SteerFaultStatus: required-interface=SRI_SteerFaultStatus
      RP_ObstacleZone: required-interface=SRI_ObstacleZone
      RP_OvercurrentFlag: required-interface=SRI_OvercurrentFlag
      RP_ActualAngle: required-interface=SRI_ActualAngle
      RP_MotorDirection: required-interface=SRI_MotorDirection
      RP_FaultReason: required-interface=SRI_FaultReason
      RP_AliveCounter: required-interface=SRI_AliveCounter
      RP_MeasuredBrake: required-interface=SRI_MeasuredBrake
      RP_RequestType: required-interface=SRI_RequestType
      RP_DeratingPercent: required-interface=SRI_DeratingPercent
      RP_Distance_cm: required-interface=SRI_Distance_cm
      RP_SensorStatus: required-interface=SRI_SensorStatus
      RP_BrakeCommandEcho: required-interface=SRI_BrakeCommandEcho
      RP_MotorFaultStatus: required-interface=SRI_MotorFaultStatus
      RP_TorqueEcho: required-interface=SRI_TorqueEcho
      RP_SC_CRC8: required-interface=SRI_SC_CRC8
      RP_CurrentDirection: required-interface=SRI_CurrentDirection
      RP_CommandedAngle: required-interface=SRI_CommandedAngle
      RP_Reason: required-interface=SRI_Reason
      RP_SignalStrength: required-interface=SRI_SignalStrength
    behavior CVC_Swc_CvcCom_IB
      init event IE_Swc_CvcCom_Init: start-on-event=Swc_CvcCom_Init
      runnable Swc_CvcCom_Init
  application sw component type CVC_Swc_CvcDcm
    behavior CVC_Swc_CvcDcm_IB
      init event IE_Swc_CvcDcm_Init: start-on-event=Swc_CvcDcm_Init
      runnable Swc_CvcDcm_Init
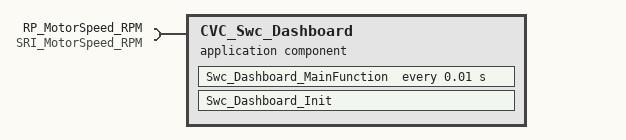
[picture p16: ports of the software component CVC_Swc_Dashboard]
  application sw component type CVC_Swc_Dashboard
    require port RP_MotorSpeed_RPM: required-interface=SRI_MotorSpeed_RPM
    behavior CVC_Swc_Dashboard_IB
      timing event TE_Swc_Dashboard_MainFunction_10ms: start-on-event=Swc_Dashboard_MainFunction, period=0.01
      init event IE_Swc_Dashboard_Init: start-on-event=Swc_Dashboard_Init
      runnable Swc_Dashboard_MainFunction
      runnable Swc_Dashboard_Init
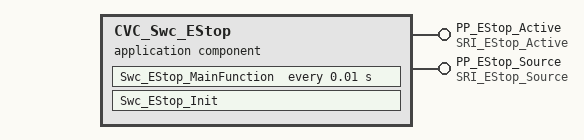
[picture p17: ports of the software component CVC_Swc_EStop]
  application sw component type CVC_Swc_EStop
    provide port PP_EStop_Active: provided-interface=SRI_EStop_Active
    provide port PP_EStop_Source: provided-interface=SRI_EStop_Source
    behavior CVC_Swc_EStop_IB
      timing event TE_Swc_EStop_MainFunction_10ms: start-on-event=Swc_EStop_MainFunction, period=0.01
      init event IE_Swc_EStop_Init: start-on-event=Swc_EStop_Init
      runnable Swc_EStop_MainFunction
      runnable Swc_EStop_Init
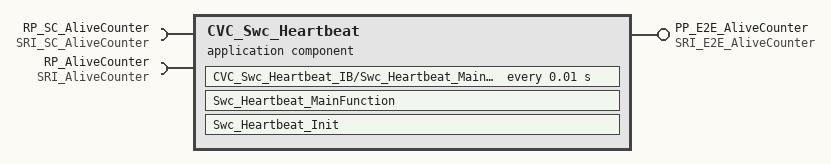
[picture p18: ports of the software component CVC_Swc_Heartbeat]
  application sw component type CVC_Swc_Heartbeat
    provide port PP_E2E_AliveCounter: provided-interface=SRI_E2E_AliveCounter
    require port RP_SC_AliveCounter: required-interface=SRI_SC_AliveCounter
    require port RP_AliveCounter: required-interface=SRI_AliveCounter
    behavior CVC_Swc_Heartbeat_IB
      timing event TE_Swc_Heartbeat_MainFunction_10ms: start-on-event=CVC_Swc_Heartbeat_IB/Swc_Heartbeat_MainFunction, period=0.01
      init event IE_Swc_Heartbeat_Init: start-on-event=Swc_Heartbeat_Init
      runnable Swc_Heartbeat_MainFunction
      runnable Swc_Heartbeat_Init
  application sw component type CVC_Swc_Nvm
    behavior CVC_Swc_Nvm_IB
      init event IE_Swc_Nvm_Init: start-on-event=Swc_Nvm_Init
      runnable Swc_Nvm_Init
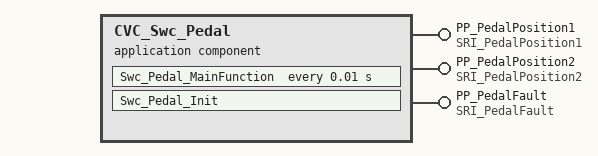
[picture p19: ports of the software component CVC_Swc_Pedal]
  application sw component type CVC_Swc_Pedal
    provide port PP_PedalPosition1: provided-interface=SRI_PedalPosition1
    provide port PP_PedalPosition2: provided-interface=SRI_PedalPosition2
    provide port PP_PedalFault: provided-interface=SRI_PedalFault
    behavior CVC_Swc_Pedal_IB
      timing event TE_Swc_Pedal_MainFunction_10ms: start-on-event=Swc_Pedal_MainFunction, period=0.01
      init event IE_Swc_Pedal_Init: start-on-event=Swc_Pedal_Init
      runnable Swc_Pedal_MainFunction
      runnable Swc_Pedal_Init
  application sw component type CVC_Swc_Scheduler
    behavior CVC_Swc_Scheduler_IB
      init event IE_Swc_Scheduler_Init: start-on-event=Swc_Scheduler_Init
      runnable Swc_Scheduler_Init
  application sw component type CVC_Swc_SelfTest
    behavior CVC_Swc_SelfTest_IB
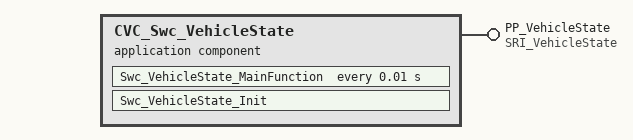
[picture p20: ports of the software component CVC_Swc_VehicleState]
  application sw component type CVC_Swc_VehicleState
    provide port PP_VehicleState: provided-interface=SRI_VehicleState
    behavior CVC_Swc_VehicleState_IB
      timing event TE_Swc_VehicleState_MainFunction_10ms: start-on-event=Swc_VehicleState_MainFunction, period=0.01
      init event IE_Swc_VehicleState_Init: start-on-event=Swc_VehicleState_Init
      runnable Swc_VehicleState_MainFunction
      runnable Swc_VehicleState_Init
  application sw component type CVC_Swc_Watchdog
    behavior CVC_Swc_Watchdog_IB
      init event IE_Swc_Watchdog_Init: start-on-event=Swc_Watchdog_Init
      runnable Swc_Watchdog_Init
package /Taktflow/SWCs/FZC
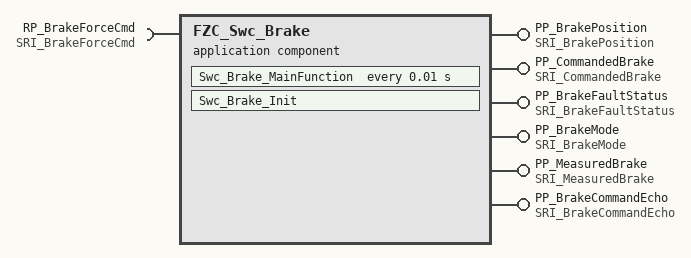
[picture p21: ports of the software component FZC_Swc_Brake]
  application sw component type FZC_Swc_Brake
    6 x provide port:
      PP_BrakePosition: provided-interface=SRI_BrakePosition
      PP_CommandedBrake: provided-interface=SRI_CommandedBrake
      PP_BrakeFaultStatus: provided-interface=SRI_BrakeFaultStatus
      PP_BrakeMode: provided-interface=SRI_BrakeMode
      PP_MeasuredBrake: provided-interface=SRI_MeasuredBrake
      PP_BrakeCommandEcho: provided-interface=SRI_BrakeCommandEcho
    require port RP_BrakeForceCmd: required-interface=SRI_BrakeForceCmd
    behavior FZC_Swc_Brake_IB
      timing event TE_Swc_Brake_MainFunction_10ms: start-on-event=Swc_Brake_MainFunction, period=0.01
      init event IE_Swc_Brake_Init: start-on-event=Swc_Brake_Init
      runnable Swc_Brake_MainFunction
      runnable Swc_Brake_Init
  application sw component type FZC_Swc_Buzzer
    behavior FZC_Swc_Buzzer_IB
      timing event TE_Swc_Buzzer_MainFunction_10ms: start-on-event=Swc_Buzzer_MainFunction, period=0.01
      init event IE_Swc_Buzzer_Init: start-on-event=Swc_Buzzer_Init
      runnable Swc_Buzzer_MainFunction
      runnable Swc_Buzzer_Init
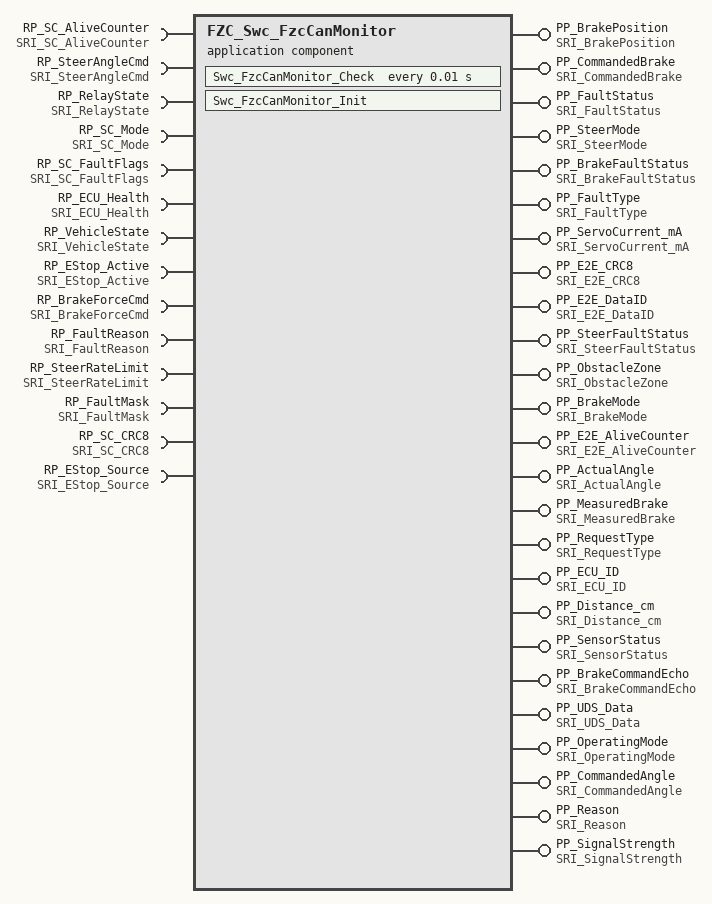
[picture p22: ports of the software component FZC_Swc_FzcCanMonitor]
  application sw component type FZC_Swc_FzcCanMonitor
    25 x provide port:
      PP_BrakePosition: provided-interface=SRI_BrakePosition
      PP_CommandedBrake: provided-interface=SRI_CommandedBrake
      PP_FaultStatus: provided-interface=SRI_FaultStatus
      PP_SteerMode: provided-interface=SRI_SteerMode
      PP_BrakeFaultStatus: provided-interface=SRI_BrakeFaultStatus
      PP_FaultType: provided-interface=SRI_FaultType
      PP_ServoCurrent_mA: provided-interface=SRI_ServoCurrent_mA
      PP_E2E_CRC8: provided-interface=SRI_E2E_CRC8
      PP_E2E_DataID: provided-interface=SRI_E2E_DataID
      PP_SteerFaultStatus: provided-interface=SRI_SteerFaultStatus
      PP_ObstacleZone: provided-interface=SRI_ObstacleZone
      PP_BrakeMode: provided-interface=SRI_BrakeMode
      PP_E2E_AliveCounter: provided-interface=SRI_E2E_AliveCounter
      PP_ActualAngle: provided-interface=SRI_ActualAngle
      PP_MeasuredBrake: provided-interface=SRI_MeasuredBrake
      PP_RequestType: provided-interface=SRI_RequestType
      PP_ECU_ID: provided-interface=SRI_ECU_ID
      PP_Distance_cm: provided-interface=SRI_Distance_cm
      PP_SensorStatus: provided-interface=SRI_SensorStatus
      PP_BrakeCommandEcho: provided-interface=SRI_BrakeCommandEcho
      PP_UDS_Data: provided-interface=SRI_UDS_Data
      PP_OperatingMode: provided-interface=SRI_OperatingMode
      PP_CommandedAngle: provided-interface=SRI_CommandedAngle
      PP_Reason: provided-interface=SRI_Reason
      PP_SignalStrength: provided-interface=SRI_SignalStrength
    14 x require port:
      RP_SC_AliveCounter: required-interface=SRI_SC_AliveCounter
      RP_SteerAngleCmd: required-interface=SRI_SteerAngleCmd
      RP_RelayState: required-interface=SRI_RelayState
      RP_SC_Mode: required-interface=SRI_SC_Mode
      RP_SC_FaultFlags: required-interface=SRI_SC_FaultFlags
      RP_ECU_Health: required-interface=SRI_ECU_Health
      RP_VehicleState: required-interface=SRI_VehicleState
      RP_EStop_Active: required-interface=SRI_EStop_Active
      RP_BrakeForceCmd: required-interface=SRI_BrakeForceCmd
      RP_FaultReason: required-interface=SRI_FaultReason
      RP_SteerRateLimit: required-interface=SRI_SteerRateLimit
      RP_FaultMask: required-interface=SRI_FaultMask
      RP_SC_CRC8: required-interface=SRI_SC_CRC8
      RP_EStop_Source: required-interface=SRI_EStop_Source
    behavior FZC_Swc_FzcCanMonitor_IB
      timing event TE_Swc_FzcCanMonitor_Check_10ms: start-on-event=Swc_FzcCanMonitor_Check, period=0.01
      init event IE_Swc_FzcCanMonitor_Init: start-on-event=Swc_FzcCanMonitor_Init
      runnable Swc_FzcCanMonitor_Check
      runnable Swc_FzcCanMonitor_Init
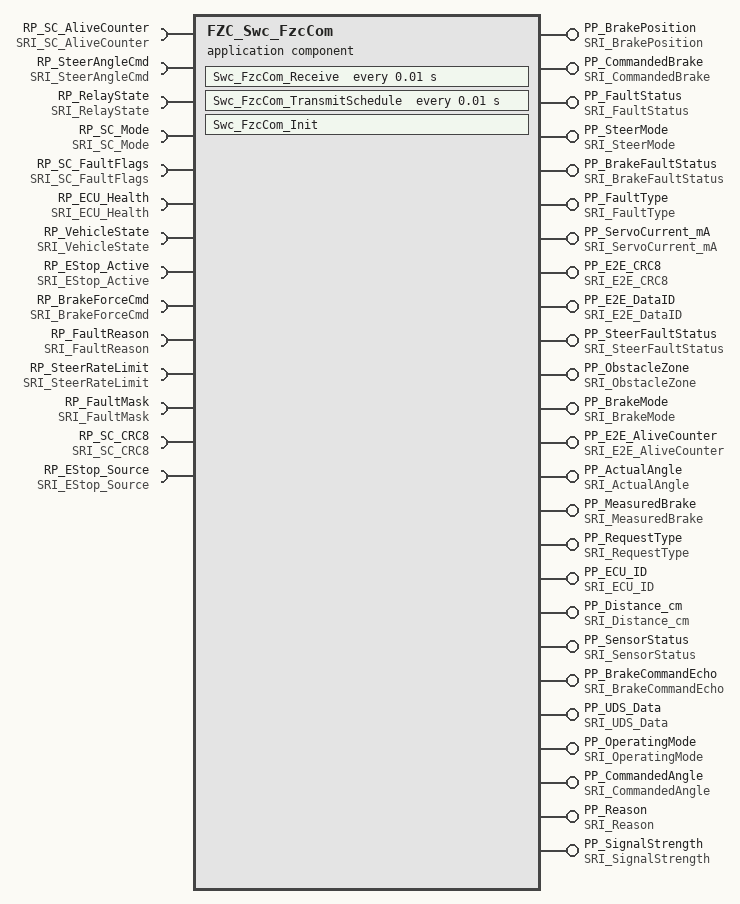
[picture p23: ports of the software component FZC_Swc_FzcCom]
  application sw component type FZC_Swc_FzcCom
    25 x provide port:
      PP_BrakePosition: provided-interface=SRI_BrakePosition
      PP_CommandedBrake: provided-interface=SRI_CommandedBrake
      PP_FaultStatus: provided-interface=SRI_FaultStatus
      PP_SteerMode: provided-interface=SRI_SteerMode
      PP_BrakeFaultStatus: provided-interface=SRI_BrakeFaultStatus
      PP_FaultType: provided-interface=SRI_FaultType
      PP_ServoCurrent_mA: provided-interface=SRI_ServoCurrent_mA
      PP_E2E_CRC8: provided-interface=SRI_E2E_CRC8
      PP_E2E_DataID: provided-interface=SRI_E2E_DataID
      PP_SteerFaultStatus: provided-interface=SRI_SteerFaultStatus
      PP_ObstacleZone: provided-interface=SRI_ObstacleZone
      PP_BrakeMode: provided-interface=SRI_BrakeMode
      PP_E2E_AliveCounter: provided-interface=SRI_E2E_AliveCounter
      PP_ActualAngle: provided-interface=SRI_ActualAngle
      PP_MeasuredBrake: provided-interface=SRI_MeasuredBrake
      PP_RequestType: provided-interface=SRI_RequestType
      PP_ECU_ID: provided-interface=SRI_ECU_ID
      PP_Distance_cm: provided-interface=SRI_Distance_cm
      PP_SensorStatus: provided-interface=SRI_SensorStatus
      PP_BrakeCommandEcho: provided-interface=SRI_BrakeCommandEcho
      PP_UDS_Data: provided-interface=SRI_UDS_Data
      PP_OperatingMode: provided-interface=SRI_OperatingMode
      PP_CommandedAngle: provided-interface=SRI_CommandedAngle
      PP_Reason: provided-interface=SRI_Reason
      PP_SignalStrength: provided-interface=SRI_SignalStrength
    14 x require port:
      RP_SC_AliveCounter: required-interface=SRI_SC_AliveCounter
      RP_SteerAngleCmd: required-interface=SRI_SteerAngleCmd
      RP_RelayState: required-interface=SRI_RelayState
      RP_SC_Mode: required-interface=SRI_SC_Mode
      RP_SC_FaultFlags: required-interface=SRI_SC_FaultFlags
      RP_ECU_Health: required-interface=SRI_ECU_Health
      RP_VehicleState: required-interface=SRI_VehicleState
      RP_EStop_Active: required-interface=SRI_EStop_Active
      RP_BrakeForceCmd: required-interface=SRI_BrakeForceCmd
      RP_FaultReason: required-interface=SRI_FaultReason
      RP_SteerRateLimit: required-interface=SRI_SteerRateLimit
      RP_FaultMask: required-interface=SRI_FaultMask
      RP_SC_CRC8: required-interface=SRI_SC_CRC8
      RP_EStop_Source: required-interface=SRI_EStop_Source
    behavior FZC_Swc_FzcCom_IB
      timing event TE_Swc_FzcCom_Receive_10ms: start-on-event=Swc_FzcCom_Receive, period=0.01
      timing event TE_Swc_FzcCom_TransmitSchedule_10ms: start-on-event=Swc_FzcCom_TransmitSchedule, period=0.01
      init event IE_Swc_FzcCom_Init: start-on-event=Swc_FzcCom_Init
      runnable Swc_FzcCom_Receive
      runnable Swc_FzcCom_TransmitSchedule
      runnable Swc_FzcCom_Init
  application sw component type FZC_Swc_FzcDcm
    behavior FZC_Swc_FzcDcm_IB
      init event IE_Swc_FzcDcm_Init: start-on-event=Swc_FzcDcm_Init
      runnable Swc_FzcDcm_Init
  application sw component type FZC_Swc_FzcNvm
    behavior FZC_Swc_FzcNvm_IB
      init event IE_Swc_FzcNvm_Init: start-on-event=Swc_FzcNvm_Init
      runnable Swc_FzcNvm_Init
  application sw component type FZC_Swc_FzcSafety
    behavior FZC_Swc_FzcSafety_IB
      timing event TE_Swc_FzcSafety_MainFunction_10ms: start-on-event=Swc_FzcSafety_MainFunction, period=0.01
      init event IE_Swc_FzcSafety_Init: start-on-event=Swc_FzcSafety_Init
      runnable Swc_FzcSafety_MainFunction
      runnable Swc_FzcSafety_Init
  application sw component type FZC_Swc_FzcScheduler
    behavior FZC_Swc_FzcScheduler_IB
      init event IE_Swc_FzcScheduler_Init: start-on-event=Swc_FzcScheduler_Init
      runnable Swc_FzcScheduler_Init
  application sw component type FZC_Swc_FzcSensorFeeder
    behavior FZC_Swc_FzcSensorFeeder_IB
      timing event TE_Swc_FzcSensorFeeder_MainFunction_10ms: start-on-event=Swc_FzcSensorFeeder_MainFunction, period=0.01
      init event IE_Swc_FzcSensorFeeder_Init: start-on-event=Swc_FzcSensorFeeder_Init
      runnable Swc_FzcSensorFeeder_MainFunction
      runnable Swc_FzcSensorFeeder_Init
  application sw component type FZC_Swc_Heartbeat
    provide port PP_E2E_AliveCounter: provided-interface=SRI_E2E_AliveCounter
    require port RP_SC_AliveCounter: required-interface=SRI_SC_AliveCounter
    behavior FZC_Swc_Heartbeat_IB
      timing event TE_Swc_Heartbeat_MainFunction_10ms: start-on-event=FZC_Swc_Heartbeat_IB/Swc_Heartbeat_MainFunction, period=0.01
      runnable Swc_Heartbeat_MainFunction
  application sw component type FZC_Swc_Lidar
    behavior FZC_Swc_Lidar_IB
      timing event TE_Swc_Lidar_MainFunction_10ms: start-on-event=Swc_Lidar_MainFunction, period=0.01
      init event IE_Swc_Lidar_Init: start-on-event=Swc_Lidar_Init
      runnable Swc_Lidar_MainFunction
      runnable Swc_Lidar_Init
  application sw component type FZC_Swc_Steering
    provide port PP_SteerMode: provided-interface=SRI_SteerMode
    provide port PP_SteerFaultStatus: provided-interface=SRI_SteerFaultStatus
    require port RP_SteerAngleCmd: required-interface=SRI_SteerAngleCmd
    require port RP_SteerRateLimit: required-interface=SRI_SteerRateLimit
    behavior FZC_Swc_Steering_IB
      timing event TE_Swc_Steering_MainFunction_10ms: start-on-event=Swc_Steering_MainFunction, period=0.01
      init event IE_Swc_Steering_Init: start-on-event=Swc_Steering_Init
      runnable Swc_Steering_MainFunction
      runnable Swc_Steering_Init
package /Taktflow/SWCs/RZC
  application sw component type RZC_Swc_Battery
    provide port PP_BatteryStatus: provided-interface=SRI_BatteryStatus
    provide port PP_BatteryVoltage_mV: provided-interface=SRI_BatteryVoltage_mV
    behavior RZC_Swc_Battery_IB
      timing event TE_Swc_Battery_MainFunction_100ms: start-on-event=Swc_Battery_MainFunction, period=0.1
      init event IE_Swc_Battery_Init: start-on-event=Swc_Battery_Init
      runnable Swc_Battery_MainFunction
      runnable Swc_Battery_Init
  application sw component type RZC_Swc_CurrentMonitor
    provide port PP_Current_mA: provided-interface=SRI_Current_mA
    provide port PP_OvercurrentFlag: provided-interface=SRI_OvercurrentFlag
    provide port PP_CurrentDirection: provided-interface=SRI_CurrentDirection
    behavior RZC_Swc_CurrentMonitor_IB
      timing event TE_Swc_CurrentMonitor_MainFunction_1ms: start-on-event=Swc_CurrentMonitor_MainFunction, period=0.001
      init event IE_Swc_CurrentMonitor_Init: start-on-event=Swc_CurrentMonitor_Init
      runnable Swc_CurrentMonitor_MainFunction
      runnable Swc_CurrentMonitor_Init
  application sw component type RZC_Swc_Encoder
    provide port PP_MotorSpeed_RPM: provided-interface=SRI_MotorSpeed_RPM
    require port RP_SpeedLimit: required-interface=SRI_SpeedLimit
    behavior RZC_Swc_Encoder_IB
      timing event TE_Swc_Encoder_MainFunction_10ms: start-on-event=Swc_Encoder_MainFunction, period=0.01
      init event IE_Swc_Encoder_Init: start-on-event=Swc_Encoder_Init
      runnable Swc_Encoder_MainFunction
      runnable Swc_Encoder_Init
  application sw component type RZC_Swc_Heartbeat
    provide port PP_E2E_AliveCounter: provided-interface=SRI_E2E_AliveCounter
    require port RP_SC_AliveCounter: required-interface=SRI_SC_AliveCounter
    behavior RZC_Swc_Heartbeat_IB
      timing event TE_Swc_Heartbeat_MainFunction_50ms: start-on-event=RZC_Swc_Heartbeat_IB/Swc_Heartbeat_MainFunction, period=0.05
      runnable Swc_Heartbeat_MainFunction
  application sw component type RZC_Swc_Motor
    5 x provide port:
      PP_MotorEnable: provided-interface=SRI_MotorEnable
      PP_MotorSpeed_RPM: provided-interface=SRI_MotorSpeed_RPM
      PP_MotorDirection: provided-interface=SRI_MotorDirection
      PP_MotorFaultStatus: provided-interface=SRI_MotorFaultStatus
      PP_TorqueEcho: provided-interface=SRI_TorqueEcho
    require port RP_TorqueRequest: required-interface=SRI_TorqueRequest
    require port RP_TorqueLimit: required-interface=SRI_TorqueLimit
    behavior RZC_Swc_Motor_IB
      timing event TE_Swc_Motor_MainFunction_10ms: start-on-event=Swc_Motor_MainFunction, period=0.01
      init event IE_Swc_Motor_Init: start-on-event=Swc_Motor_Init
      runnable Swc_Motor_MainFunction
      runnable Swc_Motor_Init
  application sw component type RZC_Swc_RzcCom
    20 x provide port:
      PP_Current_mA: provided-interface=SRI_Current_mA
      PP_BatteryStatus: provided-interface=SRI_BatteryStatus
      PP_MotorEnable: provided-interface=SRI_MotorEnable
      PP_WindingTemp1_C: provided-interface=SRI_WindingTemp1_C
      PP_WindingTemp2_C: provided-interface=SRI_WindingTemp2_C
      PP_BatteryVoltage_mV: provided-interface=SRI_BatteryVoltage_mV
      PP_FaultStatus: provided-interface=SRI_FaultStatus
      PP_MotorSpeed_RPM: provided-interface=SRI_MotorSpeed_RPM
      PP_E2E_CRC8: provided-interface=SRI_E2E_CRC8
      PP_E2E_DataID: provided-interface=SRI_E2E_DataID
      PP_E2E_AliveCounter: provided-interface=SRI_E2E_AliveCounter
      PP_OvercurrentFlag: provided-interface=SRI_OvercurrentFlag
      PP_MotorDirection: provided-interface=SRI_MotorDirection
      PP_DeratingPercent: provided-interface=SRI_DeratingPercent
      PP_ECU_ID: provided-interface=SRI_ECU_ID
      PP_MotorFaultStatus: provided-interface=SRI_MotorFaultStatus
      PP_TorqueEcho: provided-interface=SRI_TorqueEcho
      PP_UDS_Data: provided-interface=SRI_UDS_Data
      PP_OperatingMode: provided-interface=SRI_OperatingMode
      PP_CurrentDirection: provided-interface=SRI_CurrentDirection
    18 x require port:
      RP_PedalPosition1: required-interface=SRI_PedalPosition1
      RP_Direction: required-interface=SRI_Direction
      RP_SC_AliveCounter: required-interface=SRI_SC_AliveCounter
      RP_PedalPosition2: required-interface=SRI_PedalPosition2
      RP_RelayState: required-interface=SRI_RelayState
      RP_PedalFault: required-interface=SRI_PedalFault
      RP_SpeedLimit: required-interface=SRI_SpeedLimit
      RP_SC_Mode: required-interface=SRI_SC_Mode
      RP_SC_FaultFlags: required-interface=SRI_SC_FaultFlags
      RP_ECU_Health: required-interface=SRI_ECU_Health
      RP_VehicleState: required-interface=SRI_VehicleState
      RP_EStop_Active: required-interface=SRI_EStop_Active
      RP_TorqueRequest: required-interface=SRI_TorqueRequest
      RP_FaultReason: required-interface=SRI_FaultReason
      RP_FaultMask: required-interface=SRI_FaultMask
      RP_SC_CRC8: required-interface=SRI_SC_CRC8
      RP_EStop_Source: required-interface=SRI_EStop_Source
      RP_TorqueLimit: required-interface=SRI_TorqueLimit
    behavior RZC_Swc_RzcCom_IB
      timing event TE_Swc_RzcCom_Receive_10ms: start-on-event=Swc_RzcCom_Receive, period=0.01
      timing event TE_Swc_RzcCom_TransmitSchedule_10ms: start-on-event=Swc_RzcCom_TransmitSchedule, period=0.01
      init event IE_Swc_RzcCom_Init: start-on-event=Swc_RzcCom_Init
      runnable Swc_RzcCom_Receive
      runnable Swc_RzcCom_TransmitSchedule
      runnable Swc_RzcCom_Init
  application sw component type RZC_Swc_RzcDcm
    behavior RZC_Swc_RzcDcm_IB
      init event IE_Swc_RzcDcm_Init: start-on-event=Swc_RzcDcm_Init
      runnable Swc_RzcDcm_Init
  application sw component type RZC_Swc_RzcNvm
    behavior RZC_Swc_RzcNvm_IB
      init event IE_Swc_RzcNvm_Init: start-on-event=Swc_RzcNvm_Init
      runnable Swc_RzcNvm_Init
  application sw component type RZC_Swc_RzcSafety
    behavior RZC_Swc_RzcSafety_IB
      timing event TE_Swc_RzcSafety_MainFunction_100ms: start-on-event=Swc_RzcSafety_MainFunction, period=0.1
      init event IE_Swc_RzcSafety_Init: start-on-event=Swc_RzcSafety_Init
      runnable Swc_RzcSafety_MainFunction
      runnable Swc_RzcSafety_Init
  application sw component type RZC_Swc_RzcScheduler
    behavior RZC_Swc_RzcScheduler_IB
      init event IE_Swc_RzcScheduler_Init: start-on-event=Swc_RzcScheduler_Init
      runnable Swc_RzcScheduler_Init
  application sw component type RZC_Swc_RzcSelfTest
    behavior RZC_Swc_RzcSelfTest_IB
      init event IE_Swc_RzcSelfTest_Init: start-on-event=Swc_RzcSelfTest_Init
      runnable Swc_RzcSelfTest_Init
  application sw component type RZC_Swc_RzcSensorFeeder
    behavior RZC_Swc_RzcSensorFeeder_IB
      timing event TE_Swc_RzcSensorFeeder_MainFunction_10ms: start-on-event=Swc_RzcSensorFeeder_MainFunction, period=0.01
      init event IE_Swc_RzcSensorFeeder_Init: start-on-event=Swc_RzcSensorFeeder_Init
      runnable Swc_RzcSensorFeeder_MainFunction
      runnable Swc_RzcSensorFeeder_Init
  application sw component type RZC_Swc_TempMonitor
    provide port PP_WindingTemp1_C: provided-interface=SRI_WindingTemp1_C
    provide port PP_WindingTemp2_C: provided-interface=SRI_WindingTemp2_C
    behavior RZC_Swc_TempMonitor_IB
      timing event TE_Swc_TempMonitor_MainFunction_100ms: start-on-event=Swc_TempMonitor_MainFunction, period=0.1
      init event IE_Swc_TempMonitor_Init: start-on-event=Swc_TempMonitor_Init
      runnable Swc_TempMonitor_MainFunction
      runnable Swc_TempMonitor_Init
package /Taktflow/SWCs/BCM
  application sw component type BCM_Swc_BcmCan
    behavior BCM_Swc_BcmCan_IB
  application sw component type BCM_Swc_BcmMain
    19 x provide port:
      PP_FogLightOn: provided-interface=SRI_FogLightOn
      PP_HazardActive: provided-interface=SRI_HazardActive
      PP_RightIndicator: provided-interface=SRI_RightIndicator
      PP_E2E_CRC8: provided-interface=SRI_E2E_CRC8
      PP_E2E_DataID: provided-interface=SRI_E2E_DataID
      PP_BrakeLightOn: provided-interface=SRI_BrakeLightOn
      PP_HeadlightOn: provided-interface=SRI_HeadlightOn
      PP_CentralLock: provided-interface=SRI_CentralLock
      PP_E2E_AliveCounter: provided-interface=SRI_E2E_AliveCounter
      PP_LeftIndicator: provided-interface=SRI_LeftIndicator
      PP_TailLightOn: provided-interface=SRI_TailLightOn
      PP_AliveCounter: provided-interface=SRI_AliveCounter
      PP_FrontLeftLock: provided-interface=SRI_FrontLeftLock
      PP_RearRightLock: provided-interface=SRI_RearRightLock
      PP_HeadlightLevel: provided-interface=SRI_HeadlightLevel
      PP_ECU_ID: provided-interface=SRI_ECU_ID
      PP_RearLeftLock: provided-interface=SRI_RearLeftLock
      PP_FrontRightLock: provided-interface=SRI_FrontRightLock
      PP_BlinkState: provided-interface=SRI_BlinkState
    10 x require port:
      RP_TurnSignalCmd: required-interface=SRI_TurnSignalCmd
      RP_DoorLockCmd: required-interface=SRI_DoorLockCmd
      RP_FaultMask: required-interface=SRI_FaultMask
      RP_HazardCmd: required-interface=SRI_HazardCmd
      RP_UDS_Data: required-interface=SRI_UDS_Data
      RP_VehicleState: required-interface=SRI_VehicleState
      RP_TailLightCmd: required-interface=SRI_TailLightCmd
      RP_EStop_Source: required-interface=SRI_EStop_Source
      RP_EStop_Active: required-interface=SRI_EStop_Active
      RP_HeadlightCmd: required-interface=SRI_HeadlightCmd
    behavior BCM_Swc_BcmMain_IB
  application sw component type BCM_Swc_DoorLock
    5 x provide port:
      PP_CentralLock: provided-interface=SRI_CentralLock
      PP_FrontLeftLock: provided-interface=SRI_FrontLeftLock
      PP_RearRightLock: provided-interface=SRI_RearRightLock
      PP_RearLeftLock: provided-interface=SRI_RearLeftLock
      PP_FrontRightLock: provided-interface=SRI_FrontRightLock
    require port RP_DoorLockCmd: required-interface=SRI_DoorLockCmd
    behavior BCM_Swc_DoorLock_IB
      timing event TE_Swc_DoorLock_100ms_100ms: start-on-event=Swc_DoorLock_100ms, period=0.1
      init event IE_Swc_DoorLock_Init: start-on-event=Swc_DoorLock_Init
      runnable Swc_DoorLock_100ms
      runnable Swc_DoorLock_Init
  application sw component type BCM_Swc_Indicators
    provide port PP_RightIndicator: provided-interface=SRI_RightIndicator
    provide port PP_LeftIndicator: provided-interface=SRI_LeftIndicator
    require port RP_TurnSignalCmd: required-interface=SRI_TurnSignalCmd
    behavior BCM_Swc_Indicators_IB
      timing event TE_Swc_Indicators_10ms_10ms: start-on-event=Swc_Indicators_10ms, period=0.01
      init event IE_Swc_Indicators_Init: start-on-event=Swc_Indicators_Init
      runnable Swc_Indicators_10ms
      runnable Swc_Indicators_Init
  application sw component type BCM_Swc_Lights
    5 x provide port:
      PP_FogLightOn: provided-interface=SRI_FogLightOn
      PP_BrakeLightOn: provided-interface=SRI_BrakeLightOn
      PP_HeadlightOn: provided-interface=SRI_HeadlightOn
      PP_TailLightOn: provided-interface=SRI_TailLightOn
      PP_HeadlightLevel: provided-interface=SRI_HeadlightLevel
    require port RP_TailLightCmd: required-interface=SRI_TailLightCmd
    require port RP_HeadlightCmd: required-interface=SRI_HeadlightCmd
    behavior BCM_Swc_Lights_IB
      timing event TE_Swc_Lights_10ms_10ms: start-on-event=Swc_Lights_10ms, period=0.01
      init event IE_Swc_Lights_Init: start-on-event=Swc_Lights_Init
      runnable Swc_Lights_10ms
      runnable Swc_Lights_Init
package /Taktflow/SWCs/ICU
  application sw component type ICU_Swc_Dashboard
    require port RP_MotorSpeed_RPM: required-interface=SRI_MotorSpeed_RPM
    behavior ICU_Swc_Dashboard_IB
      timing event TE_Swc_Dashboard_50ms_50ms: start-on-event=Swc_Dashboard_50ms, period=0.05
      runnable Swc_Dashboard_50ms
  application sw component type ICU_Swc_DtcDisplay
    9 x require port:
      RP_DTC_Number: required-interface=SRI_DTC_Number
      RP_FaultStatus: required-interface=SRI_FaultStatus
      RP_BrakeFaultStatus: required-interface=SRI_BrakeFaultStatus
      RP_SC_FaultFlags: required-interface=SRI_SC_FaultFlags
      RP_SteerFaultStatus: required-interface=SRI_SteerFaultStatus
      RP_DTC_Status: required-interface=SRI_DTC_Status
      RP_FaultReason: required-interface=SRI_FaultReason
      RP_MotorFaultStatus: required-interface=SRI_MotorFaultStatus
      RP_FaultMask: required-interface=SRI_FaultMask
    behavior ICU_Swc_DtcDisplay_IB
      timing event TE_Swc_DtcDisplay_50ms_50ms: start-on-event=Swc_DtcDisplay_50ms, period=0.05
      init event IE_Swc_DtcDisplay_Init: start-on-event=Swc_DtcDisplay_Init
      runnable Swc_DtcDisplay_50ms
      runnable Swc_DtcDisplay_Init
package /Taktflow/SWCs/TCU
  application sw component type TCU_Swc_DataAggregator
    behavior TCU_Swc_DataAggregator_IB
  application sw component type TCU_Swc_DtcStore
    require port RP_DTC_Number: required-interface=SRI_DTC_Number
    require port RP_DTC_Status: required-interface=SRI_DTC_Status
    behavior TCU_Swc_DtcStore_IB
      init event IE_Swc_DtcStore_Init: start-on-event=Swc_DtcStore_Init
      runnable Swc_DtcStore_Init
  application sw component type TCU_Swc_Obd2Pids
    behavior TCU_Swc_Obd2Pids_IB
      init event IE_Swc_Obd2Pids_Init: start-on-event=Swc_Obd2Pids_Init
      runnable Swc_Obd2Pids_Init
  application sw component type TCU_Swc_UdsServer
    provide port PP_UDS_Data: provided-interface=SRI_UDS_Data
    behavior TCU_Swc_UdsServer_IB
      init event IE_Swc_UdsServer_Init: start-on-event=Swc_UdsServer_Init
      runnable Swc_UdsServer_Init
